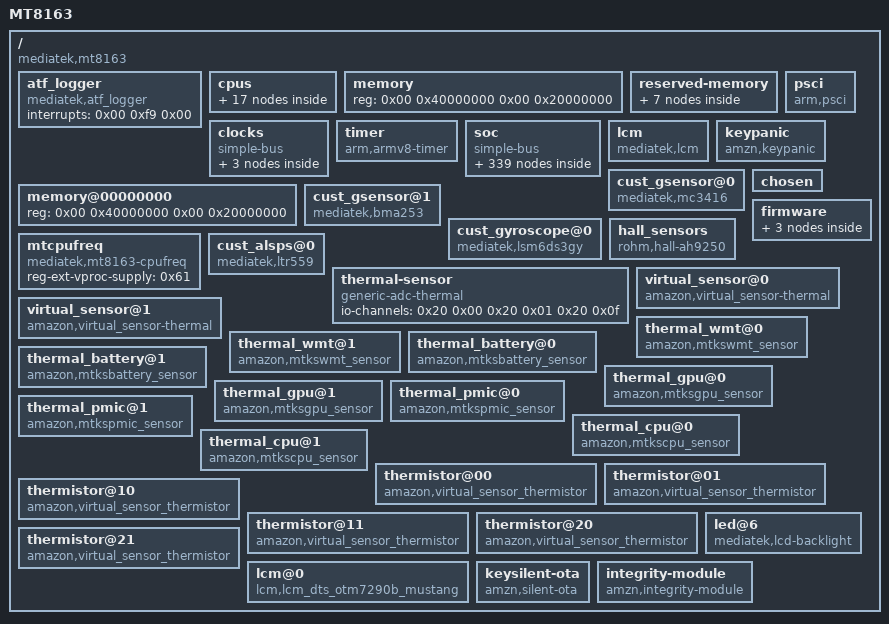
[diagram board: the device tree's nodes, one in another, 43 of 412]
/dts-v1/;

/ {
	model = "MT8163";
	compatible = "mediatek,mt8163";
	interrupt-parent = <0x01>;
	#address-cells = <0x02>;
	#size-cells = <0x02>;
	version = "hvt";

	atf_logger {
		compatible = "mediatek,atf_logger";
		interrupts = <0x00 0xf9 0x00>;
	};

	cpus {
		#address-cells = <0x01>;
		#size-cells = <0x00>;

		cpu@0 {
			device_type = "cpu";
			compatible = "arm,cortex-a53";
			next-level-cache = <0x02>;
			reg = <0x00>;
			enable-method = "mt-boot";
			cpu-idle-states = <0x03 0x03 0x04 0x04 0x04>;
			cpu-release-addr = <0x00 0x40000200>;
			clock-frequency = "M|m";
			#cooling-cells = <0x02>;
			sched-energy-costs = <0x05 0x06>;
			linux,phandle = <0x07>;
			phandle = <0x07>;
		};

		cpu@1 {
			device_type = "cpu";
			compatible = "arm,cortex-a53";
			next-level-cache = <0x02>;
			reg = <0x01>;
			enable-method = "mt-boot";
			cpu-idle-states = <0x03 0x03 0x04 0x04 0x04>;
			cpu-release-addr = <0x00 0x40000200>;
			clock-frequency = "M|m";
			sched-energy-costs = <0x05 0x06>;
			linux,phandle = <0x08>;
			phandle = <0x08>;
		};

		cpu@2 {
			device_type = "cpu";
			compatible = "arm,cortex-a53";
			next-level-cache = <0x02>;
			reg = <0x02>;
			enable-method = "mt-boot";
			cpu-idle-states = <0x03 0x03 0x04 0x04 0x04>;
			cpu-release-addr = <0x00 0x40000200>;
			clock-frequency = "M|m";
			sched-energy-costs = <0x05 0x06>;
			linux,phandle = <0x09>;
			phandle = <0x09>;
		};

		cpu@3 {
			device_type = "cpu";
			compatible = "arm,cortex-a53";
			next-level-cache = <0x02>;
			reg = <0x03>;
			enable-method = "mt-boot";
			cpu-idle-states = <0x03 0x03 0x04 0x04 0x04>;
			cpu-release-addr = <0x00 0x40000200>;
			clock-frequency = "M|m";
			sched-energy-costs = <0x05 0x06>;
			linux,phandle = <0x0a>;
			phandle = <0x0a>;
		};

		cpu-map {

			cluster0 {

				core0 {
					cpu = <0x07>;
				};

				core1 {
					cpu = <0x08>;
				};

				core2 {
					cpu = <0x09>;
				};

				core3 {
					cpu = <0x0a>;
				};
			};
		};

		l2-cache0 {
			compatible = "cache";
			linux,phandle = <0x02>;
			phandle = <0x02>;
		};

		idle-states {
			entry-method = "arm,psci";

			cpu-sleep-0-0 {
				compatible = "arm,idle-state";
				arm,psci-suspend-param = <0x10000>;
				entry-latency-us = <0x258>;
				exit-latency-us = <0x258>;
				min-residency-us = <0x4b0>;
				linux,phandle = <0x04>;
				phandle = <0x04>;
			};

			cluster-sleep-0 {
				compatible = "arm,idle-state";
				arm,psci-suspend-param = <0x2010000>;
				entry-latency-us = <0x320>;
				exit-latency-us = <0x3e8>;
				min-residency-us = <0x7d0>;
				linux,phandle = <0x03>;
				phandle = <0x03>;
			};
		};

		energy-costs {

			mt8163-core-cost0 {
				busy-cost-data = <0x400 0x00>;
				idle-cost-data = <0x00 0x00>;
				linux,phandle = <0x05>;
				phandle = <0x05>;
			};

			mt8163-cluster-cost0 {
				busy-cost-data = <0x400 0x00>;
				idle-cost-data = <0x00 0x00>;
				linux,phandle = <0x06>;
				phandle = <0x06>;
			};
		};
	};

	memory {
		device_type = "memory";
		reg = <0x00 0x40000000 0x00 0x20000000>;
	};

	reserved-memory {
		#address-cells = <0x02>;
		#size-cells = <0x02>;
		ranges;
		linux,phandle = <0x62>;
		phandle = <0x62>;

		atf-reserved-memory {
			compatible = "mediatek,mt8163-atf-reserved-memory";
			no-map;
			reg = <0x00 0x43000000 0x00 0x30000>;
			linux,phandle = <0x63>;
			phandle = <0x63>;
		};

		ram_console-reserved-memory {
			compatible = "mediatek,ram_console";
			reg = <0x00 0x44400000 0x00 0x10000>;
		};

		pstore-reserved-memory {
			compatible = "mediatek,pstore";
			reg = <0x00 0x44410000 0x00 0xe0000>;
		};

		minirdump-reserved-memory {
			compatible = "mediatek,minirdump";
			reg = <0x00 0x444f0000 0x00 0x10000>;
		};

		consys-reserve-memory {
			compatible = "mediatek,consys-reserve-memory";
			no-map;
			size = <0x00 0x200000>;
			alignment = <0x00 0x200000>;
		};

		mdump-reserved-memory {
			compatible = "amazon,mdump-reserve-memory";
			reg = <0x00 0x4bd00000 0x00 0x300000>;
			linux,phandle = <0x64>;
			phandle = <0x64>;
		};

		secure-carveout {
			compatible = "shared-secure-pool";
			reusable;
			size = <0x00 0x4c00000>;
			alignment = <0x00 0x400000>;
			linux,phandle = <0x65>;
			phandle = <0x65>;
		};
	};

	psci {
		compatible = "arm,psci";
		method = "smc";
		cpu_suspend = <0x84000001>;
		cpu_off = <0x84000002>;
		cpu_on = <0x84000003>;
		affinity_info = <0x84000004>;
	};

	clocks {
		#address-cells = <0x02>;
		#size-cells = <0x02>;
		compatible = "simple-bus";
		ranges;

		clk_null {
			compatible = "fixed-clock";
			#clock-cells = <0x00>;
			clock-frequency = <0x00>;
			linux,phandle = <0x2f>;
			phandle = <0x2f>;
		};

		clk26m {
			compatible = "fixed-clock";
			#clock-cells = <0x00>;
			clock-frequency = <0x18cba80>;
			linux,phandle = <0x21>;
			phandle = <0x21>;
		};

		clk32k {
			compatible = "fixed-clock";
			#clock-cells = <0x00>;
			clock-frequency = <0x8000>;
			linux,phandle = <0x66>;
			phandle = <0x66>;
		};
	};

	timer {
		compatible = "arm,armv8-timer";
		interrupt-parent = <0x0b>;
		interrupts = <0x01 0x0d 0xf08 0x01 0x0e 0xf08 0x01 0x0b 0xf08 0x01 0x0a 0xf08>;
		clock-frequency = <0xc65d40>;
		arm,no-tick-in-suspend;
	};

	soc {
		#address-cells = <0x02>;
		#size-cells = <0x02>;
		compatible = "simple-bus";
		ranges;

		chipid@08000000 {
			compatible = "mediatek,mt8163-chipid";
			reg = <0x00 0x8000000 0x00 0x10>;
			linux,phandle = <0x67>;
			phandle = <0x67>;
		};

		topckgen@10000000 {
			compatible = "mediatek,mt8163-topckgen";
			reg = <0x00 0x10000000 0x00 0x1000>;
			#clock-cells = <0x01>;
			linux,phandle = <0x0d>;
			phandle = <0x0d>;
		};

		infracfg@10001000 {
			compatible = "mediatek,mt8163-infracfg\0syscon";
			reg = <0x00 0x10001000 0x00 0x1000>;
			#clock-cells = <0x01>;
			#reset-cells = <0x01>;
			linux,phandle = <0x0c>;
			phandle = <0x0c>;
		};

		syscfg_pctl_a@10005000 {
			compatible = "mediatek,mt8163-pctl-a-syscfg\0syscon";
			reg = <0x00 0x10005000 0x00 0x1000>;
			linux,phandle = <0x0e>;
			phandle = <0x0e>;
		};

		toprgu@10007000 {
			compatible = "mediatek,mt8163-rgu\0mediatek,mt6589-wdt";
			reg = <0x00 0x10007000 0x00 0x1000>;
			interrupts = <0x00 0x80 0x02>;
			#reset-cells = <0x01>;
			linux,phandle = <0x4e>;
			phandle = <0x4e>;
		};

		apxgpt@10008000 {
			compatible = "mediatek,mt8163-timer\0mediatek,mt6577-timer";
			reg = <0x00 0x10008000 0x00 0x1000>;
			interrupts = <0x00 0x98 0x08>;
			clocks = <0x0c 0x06 0x0c 0x46 0x0d 0x60>;
			clock-names = "bus\0clk13m\0clk32k";
			linux,phandle = <0x68>;
			phandle = <0x68>;
		};

		pmu {
			compatible = "arm,armv8-pmuv3\0arm,cortex-a7-pmu";
			interrupts = <0x00 0x08 0x08 0x00 0x09 0x08 0x00 0x0a 0x08 0x00 0x0b 0x08>;
			interrupt-affinity = <0x07 0x08 0x09 0x0a>;
		};

		pinctrl@10005000 {
			compatible = "mediatek,mt8163-pinctrl";
			reg = <0x00 0x1000b000 0x00 0x1000>;
			mediatek,pctl-regmap = <0x0e>;
			pins-are-numbered;
			gpio-controller;
			#gpio-cells = <0x02>;
			interrupt-controller;
			#interrupt-cells = <0x02>;
			interrupts = <0x00 0x99 0x04 0x00 0x9a 0x04 0x00 0x9b 0x04>;
			pinctrl-names = "default";
			pinctrl-0 = <0x0f>;
			linux,phandle = <0x10>;
			phandle = <0x10>;

			spi1 {
				linux,phandle = <0x1e>;
				phandle = <0x1e>;

				pins_spi {
					pinmux = <0x3501 0x3601 0x3701 0x3801>;
					bias-disable;
					drive-strength = <0x02>;
					linux,phandle = <0x69>;
					phandle = <0x69>;
				};
			};

			uart0_pin_default {
				linux,phandle = <0x12>;
				phandle = <0x12>;

				pins_rx {
					pinmux = <0x4f01>;
					input-enable;
					bias-pull-up;
				};

				pins_tx {
					pinmux = <0x5001>;
				};
			};

			pinconf_default {
				linux,phandle = <0x0f>;
				phandle = <0x0f>;
			};

			eint4default {
				linux,phandle = <0x58>;
				phandle = <0x58>;
			};

			eint4 {
				linux,phandle = <0x59>;
				phandle = <0x59>;

				pins_cmd_dat {
					pinmux = <0x1a00>;
					bias-disable;
				};
			};

			bq24297_int_pin {
				linux,phandle = <0x19>;
				phandle = <0x19>;

				pins_cmd_dat {
					pinmux = <0x2b00>;
					input-enable;
					bias-pull-up;
				};
			};

			bq24297_chg_en_pin {
				linux,phandle = <0x18>;
				phandle = <0x18>;

				pins_cmd_dat {
					pinmux = <0x1800>;
					slew-rate = <0x01>;
					bias-disable;
					output-low;
				};
			};

			alspspincfg {
				linux,phandle = <0x5f>;
				phandle = <0x5f>;

				pins_cmd_dat {
					pinmux = <0x2000>;
					slew-rate = <0x00>;
					bias-pull-up = <0x00>;
				};
			};

			alspsdefaultcfg {
				linux,phandle = <0x5e>;
				phandle = <0x5e>;
			};

			audiodefault {
				linux,phandle = <0x28>;
				phandle = <0x28>;
			};

			rt551x_irq_init {
				linux,phandle = <0x15>;
				phandle = <0x15>;

				pins_cmd_dat {
					pinmux = <0x1c00>;
					bias-pull-down;
				};
			};

			pmicclkmode0 {
				linux,phandle = <0x29>;
				phandle = <0x29>;

				pins_cmd0_dat {
					pinmux = <0x700>;
				};

				pins_cmd1_dat {
					pinmux = <0x800>;
				};

				pins_cmd2_dat {
					pinmux = <0x900>;
				};
			};

			pmicclkmode1 {
				linux,phandle = <0x2a>;
				phandle = <0x2a>;

				pins_cmd0_dat {
					pinmux = <0x701>;
				};

				pins_cmd1_dat {
					pinmux = <0x801>;
				};

				pins_cmd2_dat {
					pinmux = <0x901>;
				};
			};

			camdefault {
				linux,phandle = <0x3b>;
				phandle = <0x3b>;
			};

			cam0@0 {
				linux,phandle = <0x3c>;
				phandle = <0x3c>;

				pins_cmd_dat {
					pinmux = <0x1200>;
					slew-rate = <0x01>;
					output-low;
				};
			};

			cam0@1 {
				linux,phandle = <0x3d>;
				phandle = <0x3d>;

				pins_cmd_dat {
					pinmux = <0x1200>;
					slew-rate = <0x01>;
					output-high;
				};
			};

			cam0@2 {
				linux,phandle = <0x3e>;
				phandle = <0x3e>;

				pins_cmd_dat {
					pinmux = <0x1400>;
					slew-rate = <0x01>;
					output-low;
				};
			};

			cam0@3 {
				linux,phandle = <0x3f>;
				phandle = <0x3f>;

				pins_cmd_dat {
					pinmux = <0x1400>;
					slew-rate = <0x01>;
					output-high;
				};
			};

			cam1@0 {
				linux,phandle = <0x40>;
				phandle = <0x40>;

				pins_cmd_dat {
					pinmux = <0x1300>;
					slew-rate = <0x01>;
					output-low;
				};
			};

			cam1@1 {
				linux,phandle = <0x41>;
				phandle = <0x41>;

				pins_cmd_dat {
					pinmux = <0x1300>;
					slew-rate = <0x01>;
					output-high;
				};
			};

			cam1@2 {
				linux,phandle = <0x42>;
				phandle = <0x42>;

				pins_cmd_dat {
					pinmux = <0x1500>;
					slew-rate = <0x01>;
					output-low;
				};
			};

			cam1@3 {
				linux,phandle = <0x43>;
				phandle = <0x43>;

				pins_cmd_dat {
					pinmux = <0x1500>;
					slew-rate = <0x01>;
					output-high;
				};
			};

			cam_pin_rdn0 {
				linux,phandle = <0x45>;
				phandle = <0x45>;

				pins_cmd_dat {
					pinmux = <0x6501>;
				};
			};

			cam_pin_rdp0 {
				linux,phandle = <0x46>;
				phandle = <0x46>;

				pins_cmd_dat {
					pinmux = <0x6601>;
				};
			};

			cam_pin_rcn {
				linux,phandle = <0x47>;
				phandle = <0x47>;

				pins_cmd_dat {
					pinmux = <0x6901>;
				};
			};

			cam_pin_rcp {
				linux,phandle = <0x48>;
				phandle = <0x48>;

				pins_cmd_dat {
					pinmux = <0x6a01>;
				};
			};

			cam_pin_rcn_a {
				linux,phandle = <0x49>;
				phandle = <0x49>;

				pins_cmd_dat {
					pinmux = <0x6f01>;
				};
			};

			cam_pin_rcp_a {
				linux,phandle = <0x4a>;
				phandle = <0x4a>;

				pins_cmd_dat {
					pinmux = <0x7001>;
				};
			};

			cam_pin_rdn0_a {
				linux,phandle = <0x4b>;
				phandle = <0x4b>;

				pins_cmd_dat {
					pinmux = <0x7301>;
				};
			};

			cam_pin_rdp0_a {
				linux,phandle = <0x4c>;
				phandle = <0x4c>;

				pins_cmd_dat {
					pinmux = <0x7401>;
				};
			};

			cam_pin_mclk {
				linux,phandle = <0x44>;
				phandle = <0x44>;

				pins_cmd_dat {
					pinmux = <0x7701>;
				};
			};

			default {
				linux,phandle = <0x4f>;
				phandle = <0x4f>;
			};

			eint0default {
				linux,phandle = <0x5a>;
				phandle = <0x5a>;

				pins_cmd_dat {
					pinmux = <0x1600>;
					slew-rate = <0x00>;
					bias-disable;
				};
			};

			eint@0 {
				linux,phandle = <0x1b>;
				phandle = <0x1b>;

				pins_cmd_dat {
					pinmux = <0x1600>;
					slew-rate = <0x00>;
					bias-disable;
				};
			};

			eintoutput0 {
				linux,phandle = <0x1a>;
				phandle = <0x1a>;

				pins_cmd_dat {
					pinmux = <0x1600>;
					slew-rate = <0x01>;
					output-low;
				};
			};

			eintoutput1 {
				linux,phandle = <0x5b>;
				phandle = <0x5b>;

				pins_cmd_dat {
					pinmux = <0x1600>;
					slew-rate = <0x01>;
					output-high;
				};
			};

			rstoutput0 {
				linux,phandle = <0x5c>;
				phandle = <0x5c>;

				pins_cmd_dat {
					pinmux = <0x2d00>;
					slew-rate = <0x01>;
					output-low;
				};
			};

			rstoutput1 {
				linux,phandle = <0x5d>;
				phandle = <0x5d>;

				pins_cmd_dat {
					pinmux = <0x2d00>;
					slew-rate = <0x01>;
					output-high;
				};
			};

			iddig_irq_init {
				linux,phandle = <0x23>;
				phandle = <0x23>;

				pins_cmd_dat {
					pinmux = <0x2600>;
					bias-pull-up;
				};
			};

			iddig_irq_low {
				linux,phandle = <0x24>;
				phandle = <0x24>;

				pins_cmd_dat {
					pinmux = <0x2600>;
					bias-pull-down;
				};
			};

			iddig_irq_high {
				linux,phandle = <0x25>;
				phandle = <0x25>;

				pins_cmd_dat {
					pinmux = <0x2600>;
					bias-pull-up;
				};
			};

			gpslna@0 {
				linux,phandle = <0x50>;
				phandle = <0x50>;

				pins_cmd_dat {
					pinmux = <0x600>;
					slew-rate = <0x00>;
					bias-disable;
					output-low;
				};
			};

			gpslna@1 {
				linux,phandle = <0x51>;
				phandle = <0x51>;

				pins_cmd_dat {
					pinmux = <0x600>;
					slew-rate = <0x01>;
					output-high;
				};
			};

			gpslna@2 {
				linux,phandle = <0x52>;
				phandle = <0x52>;

				pins_cmd_dat {
					pinmux = <0x600>;
					slew-rate = <0x01>;
					output-low;
				};
			};

			wifireset@0 {
				linux,phandle = <0x53>;
				phandle = <0x53>;

				pins_reset_dat {
					pinmux = <0x3c01 0x3f01 0x4001 0x4101>;
					input-enable;
					bias-pull-up;
				};
			};

			i2c0@0 {
				linux,phandle = <0x14>;
				phandle = <0x14>;

				pins1 {
					pinmux = <0x4b01 0x4c01>;
					bias-disable;
				};
			};

			i2c1@0 {
				linux,phandle = <0x16>;
				phandle = <0x16>;

				pins1 {
					pinmux = <0x3901 0x3a01>;
					bias-disable;
				};
			};

			i2c2@0 {
				linux,phandle = <0x17>;
				phandle = <0x17>;

				pins1 {
					pinmux = <0x4d01 0x4e01>;
					bias-disable;
				};
			};

			lcm_gpio@49_high {
				linux,phandle = <0x6a>;
				phandle = <0x6a>;

				pins_cmd_dat {
					pinmux = <0x3100>;
					slew-rate = <0x01>;
					output-high;
				};
			};

			lcm_gpio@49_low {
				linux,phandle = <0x6b>;
				phandle = <0x6b>;

				pins_cmd_dat {
					pinmux = <0x3100>;
					slew-rate = <0x01>;
					output-low;
				};
			};

			lcm_gpio@48_high {
				linux,phandle = <0x6c>;
				phandle = <0x6c>;

				pins_cmd_dat {
					pinmux = <0x3000>;
					slew-rate = <0x01>;
					output-high;
				};
			};

			lcm_gpio@48_low {
				linux,phandle = <0x6d>;
				phandle = <0x6d>;

				pins_cmd_dat {
					pinmux = <0x3000>;
					slew-rate = <0x01>;
					output-low;
				};
			};

			lcm_gpio@50_high {
				linux,phandle = <0x6e>;
				phandle = <0x6e>;

				pins_cmd_dat {
					pinmux = <0x3200>;
					bias-disable;
				};
			};

			lcm_gpio@50_low {
				linux,phandle = <0x6f>;
				phandle = <0x6f>;

				pins_cmd_dat {
					pinmux = <0x3200>;
					bias-disable;
				};
			};

			mmc0default {
				linux,phandle = <0x2b>;
				phandle = <0x2b>;

				pins_cmd_dat {
					pinmux = <0x8901 0x8801 0x8701 0x8601 0x8201 0x8101 0x8001 0x7f01 0x8401>;
					input-enable;
					bias-pull-up;
				};

				pins_clk {
					pinmux = <0x8501>;
					bias-pull-down;
				};

				pins_rst {
					pinmux = <0x8301>;
					bias-pull-up;
				};
			};

			mmc0@0 {
				linux,phandle = <0x2c>;
				phandle = <0x2c>;

				pins_cmd_dat {
					pinmux = <0x8901 0x8801 0x8701 0x8601 0x8201 0x8101 0x8001 0x7f01 0x8401>;
					input-enable;
					drive-strength = <0x06>;
					bias-pull-up = <0x65>;
				};

				pins_clk {
					pinmux = <0x8501>;
					drive-strength = <0x06>;
					bias-pull-down = <0x65>;
				};

				pins_rst {
					pinmux = <0x8301>;
					bias-pull-up;
				};
			};

			mmc1default {
				linux,phandle = <0x30>;
				phandle = <0x30>;

				pins_cmd_dat {
					pinmux = <0x7b01 0x7c01 0x7d01 0x7e01 0x7901>;
					input-enable;
					drive-strength = <0x06>;
					bias-pull-up = <0x65>;
				};

				pins_clk {
					pinmux = <0x7a01>;
					drive-strength = <0x06>;
					bias-pull-down = <0x66>;
				};

				pins_insert {
					pinmux = <0x3400>;
					bias-pull-up;
				};
			};

			mmc1@0 {
				linux,phandle = <0x31>;
				phandle = <0x31>;

				pins_cmd_dat {
					pinmux = <0x7b01 0x7c01 0x7d01 0x7e01 0x7901>;
					input-enable;
					drive-strength = <0x08>;
					bias-pull-up = <0x66>;
				};

				pins_clk {
					pinmux = <0x7a01>;
					drive-strength = <0x08>;
					bias-pull-down = <0x66>;
				};
			};
		};

		dramco@10004000 {
			compatible = "mediatek,mt8163-dramco";
			reg = <0x00 0x10004000 0x00 0x1000>;
			linux,phandle = <0x70>;
			phandle = <0x70>;
		};

		scpsys@10006000 {
			compatible = "mediatek,mt8163-scpsys\0syscon";
			#power-domain-cells = <0x01>;
			reg = <0x00 0x10006000 0x00 0x1000>;
			interrupts = <0x00 0xa3 0x08 0x00 0xa4 0x08 0x00 0xa5 0x08 0x00 0xa6 0x08 0x00 0xa7 0x08 0x00 0xa8 0x08 0x00 0xa9 0x08 0x00 0xaa 0x08>;
			infracfg = <0x0c>;
			clocks = <0x0d 0x46 0x0d 0x43>;
			clock-names = "mfg\0mm";
			linux,phandle = <0x27>;
			phandle = <0x27>;
		};

		hacc@1000a000 {
			compatible = "mediatek,hacc";
			reg = <0x00 0x1000a000 0x00 0x1000>;
			clocks = <0x0c 0x05>;
			clock-names = "main";
		};

		apmixedsys@1000c000 {
			compatible = "mediatek,mt8163-apmixedsys";
			reg = <0x00 0x1000c000 0x00 0x1000>;
			#clock-cells = <0x01>;
			linux,phandle = <0x1f>;
			phandle = <0x1f>;
		};

		fhctl@1000cf00 {
			compatible = "mediatek,mt8163-fhctl";
			reg = <0x00 0x1000cf00 0x00 0x100>;
		};

		pwrap@0x1000d000 {
			compatible = "mediatek,mt8163-pwrap";
			reg = <0x00 0x1000d000 0x00 0x1000>;
			reg-names = "pwrap";
			interrupts = <0x00 0xa1 0x04>;
			clocks = <0x0d 0x51 0x0c 0x01>;
			clock-names = "spi\0wrap";
			linux,phandle = <0x71>;
			phandle = <0x71>;

			mt6323 {
				compatible = "mediatek,mt6323";
				linux,phandle = <0x72>;
				phandle = <0x72>;

				pmicmt6323 {
					compatible = "mediatek,mt6323-pmic";
					interrupt-parent = <0x10>;
					interrupts = <0x18 0x04>;
					linux,phandle = <0x73>;
					phandle = <0x73>;
				};

				regulators {
					compatible = "mediatek,mt6323-regulator";

					buck_vproc {
						regulator-name = "vproc";
						regulator-min-microvolt = <0xaae60>;
						regulator-max-microvolt = <0x149970>;
						regulator-ramp-delay = <0x30d4>;
						regulator-always-on;
						regulator-boot-on;
						linux,phandle = <0x74>;
						phandle = <0x74>;
					};

					buck_vsys {
						regulator-name = "vsys";
						regulator-min-microvolt = <0x155cc0>;
						regulator-max-microvolt = <0x2d95ec>;
						regulator-ramp-delay = <0x61a8>;
						regulator-always-on;
						regulator-boot-on;
						linux,phandle = <0x75>;
						phandle = <0x75>;
					};

					buck_vpa {
						regulator-name = "vpa";
						regulator-min-microvolt = <0x7a120>;
						regulator-max-microvolt = <0x37b1d0>;
						linux,phandle = <0x76>;
						phandle = <0x76>;
					};

					ldo_vtcxo {
						regulator-name = "vtcxo";
						regulator-min-microvolt = <0x2ab980>;
						regulator-max-microvolt = <0x2ab980>;
						regulator-enable-ramp-delay = <0x5a>;
						regulator-always-on;
						regulator-boot-on;
						linux,phandle = <0x77>;
						phandle = <0x77>;
					};

					ldo_vcn28 {
						regulator-name = "vcn28";
						regulator-min-microvolt = <0x2ab980>;
						regulator-max-microvolt = <0x2ab980>;
						regulator-enable-ramp-delay = <0xb9>;
						linux,phandle = <0x55>;
						phandle = <0x55>;
					};

					ldo_vcn33_bt {
						regulator-name = "vcn33_bt";
						regulator-min-microvolt = <0x325aa0>;
						regulator-max-microvolt = <0x36ee80>;
						regulator-enable-ramp-delay = <0xb9>;
						linux,phandle = <0x56>;
						phandle = <0x56>;
					};

					ldo_vcn33_wifi {
						regulator-name = "vcn33_wifi";
						regulator-min-microvolt = <0x325aa0>;
						regulator-max-microvolt = <0x36ee80>;
						regulator-enable-ramp-delay = <0xb9>;
						linux,phandle = <0x57>;
						phandle = <0x57>;
					};

					ldo_va {
						regulator-name = "va";
						regulator-min-microvolt = <0x2ab980>;
						regulator-max-microvolt = <0x2ab980>;
						regulator-enable-ramp-delay = <0xd8>;
						regulator-always-on;
						regulator-boot-on;
						linux,phandle = <0x78>;
						phandle = <0x78>;
					};

					ldo_vcama {
						regulator-name = "vcama";
						regulator-min-microvolt = <0x16e360>;
						regulator-max-microvolt = <0x2ab980>;
						regulator-enable-ramp-delay = <0xd8>;
						linux,phandle = <0x38>;
						phandle = <0x38>;
					};

					ldo_vio28 {
						regulator-name = "vio28";
						regulator-min-microvolt = <0x2ab980>;
						regulator-max-microvolt = <0x2ab980>;
						regulator-enable-ramp-delay = <0xd8>;
						regulator-always-on;
						regulator-boot-on;
						linux,phandle = <0x79>;
						phandle = <0x79>;
					};

					ldo_vusb {
						regulator-name = "vusb";
						regulator-min-microvolt = <0x325aa0>;
						regulator-max-microvolt = <0x325aa0>;
						regulator-enable-ramp-delay = <0xd8>;
						regulator-boot-on;
						linux,phandle = <0x22>;
						phandle = <0x22>;
					};

					ldo_vmc {
						regulator-name = "vmc";
						regulator-min-microvolt = <0x1b7740>;
						regulator-max-microvolt = <0x325aa0>;
						regulator-enable-ramp-delay = <0x24>;
						regulator-boot-on;
						linux,phandle = <0x33>;
						phandle = <0x33>;
					};

					ldo_vmch {
						regulator-name = "vmch";
						regulator-min-microvolt = <0x2dc6c0>;
						regulator-max-microvolt = <0x325aa0>;
						regulator-enable-ramp-delay = <0x24>;
						regulator-boot-on;
						linux,phandle = <0x32>;
						phandle = <0x32>;
					};

					ldo_vemc3v3 {
						regulator-name = "vemc3v3";
						regulator-min-microvolt = <0x2dc6c0>;
						regulator-max-microvolt = <0x325aa0>;
						regulator-enable-ramp-delay = <0x24>;
						regulator-boot-on;
						linux,phandle = <0x2d>;
						phandle = <0x2d>;
					};

					ldo_vgp1 {
						regulator-name = "vgp1";
						regulator-min-microvolt = <0x124f80>;
						regulator-max-microvolt = <0x325aa0>;
						regulator-enable-ramp-delay = <0xd8>;
						linux,phandle = <0x60>;
						phandle = <0x60>;
					};

					ldo_vgp2 {
						regulator-name = "vgp2";
						regulator-min-microvolt = <0x124f80>;
						regulator-max-microvolt = <0x2dc6c0>;
						regulator-enable-ramp-delay = <0xd8>;
						linux,phandle = <0x1c>;
						phandle = <0x1c>;
					};

					ldo_vgp3 {
						regulator-name = "vgp3";
						regulator-min-microvolt = <0x124f80>;
						regulator-max-microvolt = <0x1b7740>;
						regulator-enable-ramp-delay = <0xd8>;
						linux,phandle = <0x4d>;
						phandle = <0x4d>;
					};

					ldo_vcn18 {
						regulator-name = "vcn18";
						regulator-min-microvolt = <0x1b7740>;
						regulator-max-microvolt = <0x1b7740>;
						regulator-enable-ramp-delay = <0xd8>;
						linux,phandle = <0x54>;
						phandle = <0x54>;
					};

					ldo_vsim1 {
						regulator-name = "vsim1";
						regulator-min-microvolt = <0x1b7740>;
						regulator-max-microvolt = <0x2dc6c0>;
						regulator-enable-ramp-delay = <0xd8>;
						linux,phandle = <0x7a>;
						phandle = <0x7a>;
					};

					ldo_vsim2 {
						regulator-name = "vsim2";
						regulator-min-microvolt = <0x1b7740>;
						regulator-max-microvolt = <0x2dc6c0>;
						regulator-enable-ramp-delay = <0xd8>;
						linux,phandle = <0x7b>;
						phandle = <0x7b>;
					};

					ldo_vrtc {
						regulator-name = "vrtc";
						regulator-min-microvolt = <0x2ab980>;
						regulator-max-microvolt = <0x2ab980>;
						regulator-always-on;
						regulator-boot-on;
						linux,phandle = <0x7c>;
						phandle = <0x7c>;
					};

					ldo_vcamaf {
						regulator-name = "vcamaf";
						regulator-min-microvolt = <0x124f80>;
						regulator-max-microvolt = <0x325aa0>;
						regulator-enable-ramp-delay = <0xd8>;
						linux,phandle = <0x1d>;
						phandle = <0x1d>;
					};

					ldo_vibr {
						regulator-name = "vibr";
						regulator-min-microvolt = <0x124f80>;
						regulator-max-microvolt = <0x325aa0>;
						regulator-enable-ramp-delay = <0x24>;
						linux,phandle = <0x7d>;
						phandle = <0x7d>;
					};

					ldo_vrf18 {
						regulator-name = "vrf18";
						regulator-min-microvolt = <0x1bd8e8>;
						regulator-max-microvolt = <0x1bd8e8>;
						regulator-enable-ramp-delay = <0xbb>;
						regulator-boot-on;
						linux,phandle = <0x7e>;
						phandle = <0x7e>;
					};

					ldo_vm {
						regulator-name = "vm";
						regulator-min-microvolt = <0x124f80>;
						regulator-max-microvolt = <0x1b7740>;
						regulator-enable-ramp-delay = <0xd8>;
						regulator-always-on;
						regulator-boot-on;
						linux,phandle = <0x7f>;
						phandle = <0x7f>;
					};

					ldo_vio18 {
						regulator-name = "vio18";
						regulator-min-microvolt = <0x1b7740>;
						regulator-max-microvolt = <0x1b7740>;
						regulator-enable-ramp-delay = <0xd8>;
						regulator-always-on;
						regulator-boot-on;
						linux,phandle = <0x2e>;
						phandle = <0x2e>;
					};

					ldo_vcamd {
						regulator-name = "vcamd";
						regulator-min-microvolt = <0x124f80>;
						regulator-max-microvolt = <0x1b7740>;
						regulator-enable-ramp-delay = <0xd8>;
						linux,phandle = <0x39>;
						phandle = <0x39>;
					};

					ldo_vcamio {
						regulator-name = "vcamio";
						regulator-min-microvolt = <0x1b7740>;
						regulator-max-microvolt = <0x1b7740>;
						regulator-enable-ramp-delay = <0xd8>;
						linux,phandle = <0x3a>;
						phandle = <0x3a>;
					};
				};
			};
		};

		devapc_ao@1000e000 {
			compatible = "mediatek,mt8163-devapc_ao";
			reg = <0x00 0x1000e000 0x00 0x1000>;
		};

		ddrphy@1000f000 {
			compatible = "mediatek,mt8163-ddrphy\0mediatek,ddrphy";
			reg = <0x00 0x1000f000 0x00 0x1000>;
			clocks = <0x0c 0x36>;
			clock-names = "dramc_f26m";
			linux,phandle = <0x80>;
			phandle = <0x80>;
		};

		keypad@10010000 {
			compatible = "mediatek,mt8163-keypad\0mediatek,kp";
			reg = <0x00 0x10010000 0x00 0x1000>;
			interrupts = <0x00 0xa2 0x02>;
			mediatek,kpd-key-debounce = <0x400>;
			mediatek,kpd-sw-pwrkey = <0x74>;
			mediatek,kpd-hw-pwrkey = <0x08>;
			mediatek,kpd-sw-rstkey = <0x73>;
			mediatek,kpd-hw-rstkey = <0x11>;
			mediatek,kpd-use-extend-type = <0x00>;
			mediatek,kpd-hw-map-num = <0x48>;
			mediatek,kpd-hw-init-map = <0x72 0x00 0x00 0x00 0x00 0x00 0x00 0x00 0x00 0x00 0x00 0x00 0x00 0x00 0x00 0x00 0x00 0x00 0x00 0x00 0x00 0x00 0x00 0x00 0x00 0x00 0x00 0x00 0x00 0x00 0x00 0x00 0x00 0x00 0x00 0x00 0x00 0x00 0x00 0x00 0x00 0x00 0x00 0x00 0x00 0x00 0x00 0x00 0x00 0x00 0x00 0x00 0x00 0x00 0x00 0x00 0x00 0x00 0x00 0x00 0x00 0x00 0x00 0x00 0x00 0x00 0x00 0x00 0x00 0x00 0x00 0x00>;
			mediatek,kpd-pwrkey-eint-gpio = <0x00>;
			mediatek,kpd-pwkey-gpio-din = <0x00>;
			mediatek,kpd-hw-dl-key0 = <0x00>;
			mediatek,kpd-hw-dl-key1 = <0x11>;
			mediatek,kpd-hw-dl-key2 = <0x08>;
			mediatek,kpd-hw-recovery-key = <0x00>;
			mediatek,kpd-hw-factory-key = <0x11>;
			linux,phandle = <0x81>;
			phandle = <0x81>;
		};

		md32@10020000 {
			compatible = "mediatek,mt8163-md32";
			reg = <0x00 0x10020000 0x00 0x38000 0x00 0x10058000 0x00 0x400 0x00 0x10059000 0x00 0x400>;
			interrupts = <0x00 0xae 0x04>;
			clocks = <0x0c 0x04>;
			clock-names = "sys";
			status = "okay";
			linux,phandle = <0x82>;
			phandle = <0x82>;
		};

		mcucfg@10200000 {
			compatible = "mediatek,mt8173-mcucfg\0syscon";
			reg = <0x00 0x10200000 0x00 0x1000>;
			linux,phandle = <0x83>;
			phandle = <0x83>;
		};

		cpuxgpt@10200000 {
			compatible = "mediatek,mt8163-cpuxgpt";
			interrupts = <0x00 0x40 0x04 0x00 0x41 0x04 0x00 0x42 0x04 0x00 0x43 0x04>;
			linux,phandle = <0x84>;
			phandle = <0x84>;
		};

		lastpc@10200000 {
			compatible = "mediatek,mt8163-mcucfg";
			reg = <0x00 0x10200000 0x00 0x200>;
			linux,phandle = <0x85>;
			phandle = <0x85>;
		};

		intpol-controller@10200620 {
			compatible = "mediatek,mt8163-sysirq\0mediatek,mt6577-sysirq";
			interrupt-controller;
			#interrupt-cells = <0x03>;
			interrupt-parent = <0x0b>;
			reg = <0x00 0x10200620 0x00 0x20>;
			linux,phandle = <0x01>;
			phandle = <0x01>;
		};

		emi@10203000 {
			compatible = "mediatek,mt8163-emi\0mediatek,emi";
			reg = <0x00 0x10203000 0x00 0x1000>;
			interrupts = <0x00 0x85 0x08>;
			linux,phandle = <0x86>;
			phandle = <0x86>;
		};

		sys_cirq@10204000 {
			compatible = "mediatek,mt8163-sys_cirq\0mediatek,mt6735-sys_cirq";
			reg = <0x00 0x10204000 0x00 0x1000>;
			interrupts = <0x00 0xf0 0x08>;
			mediatek,cirq_num = <0xa9>;
			mediatek,spi_start_offset = <0x48>;
			linux,phandle = <0x87>;
			phandle = <0x87>;
		};

		m4u@10205000 {
			cell-index = <0x00>;
			compatible = "mediatek,mt8163-m4u";
			reg = <0x00 0x10205000 0x00 0x1000>;
			interrupts = <0x00 0x93 0x08>;
		};

		devapc@10207000 {
			compatible = "mediatek,mt8163-devapc";
			reg = <0x00 0x10207000 0x00 0x1000>;
			interrupts = <0x00 0x85 0x08>;
			clocks = <0x0c 0x2b>;
			clock-names = "main";
		};

		systracker@10208000 {
			compatible = "mediatek,bus_dbg-v1";
			reg = <0x00 0x10208000 0x00 0x1000>;
			interrupts = <0x00 0x84 0x08>;
			linux,phandle = <0x88>;
			phandle = <0x88>;
		};

		dramc_nao@1020e000 {
			compatible = "mediatek,mt8163-dramc_nao\0mediatek,dramc_nao";
			reg = <0x00 0x1020e000 0x00 0x1000>;
			linux,phandle = <0x89>;
			phandle = <0x89>;
		};

		gcpu@10210000 {
			compatible = "mediatek,mt8163-gcpu";
			reg = <0x00 0x10210000 0x00 0x1000>;
			clocks = <0x0c 0x20>;
			clock-names = "main";
			linux,phandle = <0x8a>;
			phandle = <0x8a>;
		};

		gce@10212000 {
			compatible = "mediatek,mt8163-gce";
			reg = <0x00 0x10212000 0x00 0x1000>;
			interrupts = <0x00 0x8f 0x08 0x00 0x90 0x08>;
			disp_mutex_reg = <0x14015000 0x1000>;
			g3d_config_base = <0x13000000 0x00 0xffff0000>;
			mmsys_config_base = <0x14000000 0x01 0xffff0000>;
			disp_dither_base = <0x14010000 0x02 0xffff0000>;
			mm_na_base = <0x14020000 0x03 0xffff0000>;
			imgsys_base = <0x15000000 0x04 0xffff0000>;
			vdec_gcon_base = <0x16000000 0x05 0xffff0000>;
			venc_gcon_base = <0x17000000 0x06 0xffff0000>;
			conn_peri_base = <0x18000000 0x07 0xffff0000>;
			topckgen_base = <0x10000000 0x08 0xffff0000>;
			kp_base = <0x10010000 0x09 0xffff0000>;
			scp_sram_base = <0x10020000 0x0a 0xffff0000>;
			infra_na3_base = <0x10030000 0x0b 0xffff0000>;
			infra_na4_base = <0x10040000 0x0c 0xffff0000>;
			scp_base = <0x10050000 0x0d 0xffff0000>;
			mcucfg_base = <0x10200000 0x0e 0xffff0000>;
			gcpu_base = <0x10210000 0x0f 0xffff0000>;
			usb0_base = <0x11200000 0x10 0xffff0000>;
			usb_sif_base = <0x11210000 0x11 0xffff0000>;
			audio_base = <0x11220000 0x12 0xffff0000>;
			msdc0_base = <0x11230000 0x13 0xffff0000>;
			msdc1_base = <0x11240000 0x14 0xffff0000>;
			msdc2_base = <0x11250000 0x15 0xffff0000>;
			msdc3_base = <0x11260000 0x16 0xffff0000>;
			mdp_rdma0_sof = <0x00>;
			mdp_rsz0_sof = <0x01>;
			mdp_rsz1_sof = <0x02>;
			mdp_tdshp_sof = <0x03>;
			mdp_wdma_sof = <0x04>;
			mdp_wrot_sof = <0x05>;
			disp_ovl0_sof = <0x06>;
			disp_ovl1_sof = <0x07>;
			disp_rdma0_sof = <0x08>;
			disp_rdma1_sof = <0x09>;
			disp_wdma0_sof = <0x0a>;
			disp_color_sof = <0x0b>;
			disp_ccorr_sof = <0x0c>;
			disp_aal_sof = <0x0d>;
			disp_gamma_sof = <0x0e>;
			disp_dither_sof = <0x0f>;
			disp_ufoe_sof = <0x10>;
			disp_pwm0_sof = <0x11>;
			disp_wdma1_sof = <0x12>;
			ufod_rdma0_l0_sof = <0x13>;
			ufod_rdma0_l1_sof = <0x14>;
			ufod_rdma0_l2_sof = <0x15>;
			ufod_rdma0_l3_sof = <0x16>;
			ufod_rdma1_l0_sof = <0x17>;
			ufod_rdma1_l1_sof = <0x18>;
			ufod_rdma1_l2_sof = <0x19>;
			ufod_rdma1_l3_sof = <0x1a>;
			disp_dsc_sof = <0x1b>;
			mdp_rdma0_frame_done = <0x1c>;
			mdp_rsz0_frame_done = <0x1d>;
			mdp_rsz1_frame_done = <0x1e>;
			mdp_tdshp_frame_done = <0x1f>;
			mdp_wdma_frame_done = <0x20>;
			mdp_wrot_write_frame_done = <0x21>;
			mdp_wrot_read_frame_done = <0x22>;
			disp_ovl0_frame_done = <0x23>;
			disp_ovl1_frame_done = <0x24>;
			disp_rdma0_frame_done = <0x25>;
			disp_rdma1_frame_done = <0x26>;
			disp_wdma0_frame_done = <0x27>;
			disp_color_frame_done = <0x28>;
			disp_ccorr_frame_done = <0x29>;
			disp_aal_frame_done = <0x2a>;
			disp_gamma_frame_done = <0x2b>;
			disp_dither_frame_done = <0x2c>;
			disp_ufoe_frame_done = <0x2d>;
			disp_dpi0_frame_done = <0x2e>;
			disp_wdma1_frame_done = <0x2f>;
			ufod_rdma0_l0_frame_done = <0x30>;
			ufod_rdma0_l1_frame_done = <0x31>;
			ufod_rdma0_l2_frame_done = <0x32>;
			ufod_rdma0_l3_frame_done = <0x33>;
			ufod_rdma1_l0_frame_done = <0x34>;
			ufod_rdma1_l1_frame_done = <0x35>;
			ufod_rdma1_l2_frame_done = <0x36>;
			ufod_rdma1_l3_frame_done = <0x37>;
			disp_dpi1_frame_done = <0x38>;
			disp_dsc_frame_done = <0x39>;
			stream_done_0 = <0x3a>;
			stream_done_1 = <0x3b>;
			stream_done_2 = <0x3c>;
			stream_done_3 = <0x3d>;
			stream_done_4 = <0x3e>;
			stream_done_5 = <0x3f>;
			stream_done_6 = <0x40>;
			stream_done_7 = <0x41>;
			stream_done_8 = <0x42>;
			stream_done_9 = <0x43>;
			buf_underrun_event_0 = <0x44>;
			buf_underrun_event_1 = <0x45>;
			dsi0_te_event = <0x46>;
			isp_frame_done_b = <0x82>;
			isp_frame_done_a = <0x83>;
			isp_frame_done_p2_0 = <0x83>;
			isp_frame_done_p2_1 = <0x82>;
			seninf_1_fifo_full = <0x87>;
			venc_done = <0x101>;
			jpgenc_done = <0x102>;
			jpgdec_done = <0x103>;
			venc_mb_done = <0x104>;
			venc_128byte_cnt_done = <0x105>;
			clocks = <0x0c 0x09 0x11 0x00 0x11 0x01 0x11 0x02 0x11 0x03 0x11 0x04 0x11 0x05 0x11 0x06 0x11 0x08 0x11 0x07>;
			clock-names = "MT_CG_INFRA_GCE\0MT_CG_DISP0_SMI_COMMON\0MT_CG_DISP0_SMI_LARB0\0MT_CG_DISP0_CAM_MDP\0MT_CG_DISP0_MDP_RDMA\0MT_CG_DISP0_MDP_RSZ0\0MT_CG_DISP0_MDP_RSZ1\0MT_CG_DISP0_MDP_TDSHP\0MT_CG_DISP0_MDP_WROT\0MT_CG_DISP0_MDP_WDMA";
			linux,phandle = <0x8b>;
			phandle = <0x8b>;
		};

		perisys_iommu@10214000 {
			cell-index = <0x01>;
			compatible = "mediatek,mt8163-perisys_iommu";
			reg = <0x00 0x10214000 0x00 0x1000>;
			interrupts = <0x00 0x91 0x08>;
		};

		interrupt-controller@10221000 {
			compatible = "arm,gic-400";
			interrupt-controller;
			#interrupt-cells = <0x03>;
			interrupt-parent = <0x0b>;
			reg = <0x00 0x10221000 0x00 0x1000 0x00 0x10222000 0x00 0x1000 0x00 0x10224000 0x00 0x2000 0x00 0x10226000 0x00 0x2000>;
			interrupts = <0x01 0x09 0xf04>;
			linux,phandle = <0x0b>;
			phandle = <0x0b>;
		};

		btif_tx@11000700 {
			compatible = "mediatek,btif_tx";
			reg = <0x00 0x11000700 0x00 0x80>;
			interrupts = <0x00 0x6e 0x08>;
			linux,phandle = <0x8c>;
			phandle = <0x8c>;
		};

		btif_rx@11000780 {
			compatible = "mediatek,btif_rx";
			reg = <0x00 0x11000780 0x00 0x80>;
			interrupts = <0x00 0x6f 0x08>;
			linux,phandle = <0x8d>;
			phandle = <0x8d>;
		};

		dma-controller@0x11000300 {
			compatible = "mediatek,mt8163-uart-dma\0mediatek,mt6577-uart-dma";
			reg = <0x00 0x11000300 0x00 0x80 0x00 0x11000380 0x00 0x80 0x00 0x11000400 0x00 0x80 0x00 0x11000480 0x00 0x80 0x00 0x11000500 0x00 0x80 0x00 0x11000580 0x00 0x80 0x00 0x11000600 0x00 0x80 0x00 0x11000680 0x00 0x80>;
			interrupts = <0x00 0x66 0x08 0x00 0x67 0x08 0x00 0x68 0x08 0x00 0x69 0x08 0x00 0x6a 0x08 0x00 0x6b 0x08 0x00 0x6c 0x08 0x00 0x6d 0x08>;
			clocks = <0x0c 0x29>;
			clock-names = "apdma";
			#dma-cells = <0x01>;
			linux,phandle = <0x13>;
			phandle = <0x13>;
		};

		auxadc@11001000 {
			compatible = "mediatek,mt8163-auxadc\0mediatek,mt6735-auxadc";
			reg = <0x00 0x11001000 0x00 0x1000>;
			interrupts = <0x00 0x4c 0x02>;
			clocks = <0x0c 0x21>;
			clock-names = "main";
			#io-channel-cells = <0x01>;
			status = "okay";
			linux,phandle = <0x20>;
			phandle = <0x20>;
		};

		serial@11002000 {
			compatible = "mediatek,mt8163-uart\0mediatek,mt6577-uart";
			reg = <0x00 0x11002000 0x00 0x1000>;
			interrupts = <0x00 0x5b 0x08>;
			clocks = <0x0d 0x48 0x0c 0x13>;
			clock-names = "baud\0bus";
			pinctrl-names = "default";
			pinctrl-0 = <0x12>;
			status = "okay";
			linux,phandle = <0x8e>;
			phandle = <0x8e>;
		};

		serial@11003000 {
			compatible = "mediatek,mt8163-uart\0mediatek,mt6577-uart";
			reg = <0x00 0x11003000 0x00 0x1000>;
			interrupts = <0x00 0x5c 0x08>;
			clocks = <0x0d 0x48 0x0c 0x14>;
			clock-names = "baud\0bus";
			dmas = <0x13 0x02 0x13 0x03>;
			dma-names = "tx\0rx";
			status = "disabled";
			linux,phandle = <0x8f>;
			phandle = <0x8f>;
		};

		serial@11004000 {
			compatible = "mediatek,mt8163-uart\0mediatek,mt6577-uart";
			reg = <0x00 0x11004000 0x00 0x1000>;
			interrupts = <0x00 0x5d 0x08>;
			clocks = <0x0d 0x48 0x0c 0x15>;
			clock-names = "baud\0bus";
			dmas = <0x13 0x04 0x13 0x05>;
			dma-names = "tx\0rx";
			status = "disabled";
			linux,phandle = <0x90>;
			phandle = <0x90>;
		};

		serial@11005000 {
			compatible = "mediatek,mt8163-uart\0mediatek,mt6577-uart";
			reg = <0x00 0x11005000 0x00 0x1000>;
			interrupts = <0x00 0x5e 0x08>;
			clocks = <0x0d 0x48 0x0c 0x16>;
			clock-names = "baud\0bus";
			dmas = <0x13 0x06 0x13 0x07>;
			dma-names = "tx\0rx";
			status = "disabled";
			linux,phandle = <0x91>;
			phandle = <0x91>;
		};

		pwm@11006000 {
			compatible = "mediatek,pwm";
			reg = <0x00 0x11006000 0x00 0x1000>;
			interrupts = <0x00 0x4d 0x08>;
			clocks = <0x0c 0x0f 0x0c 0x10 0x0c 0x11 0x0c 0x12>;
			clock-names = "pwm1\0pwm2\0pwm3\0main";
			linux,phandle = <0x92>;
			phandle = <0x92>;
		};

		i2c@11007000 {
			compatible = "mediatek,mt8173-i2c";
			reg = <0x00 0x11007000 0x00 0x70 0x00 0x11000180 0x00 0x80>;
			interrupts = <0x00 0x54 0x08>;
			clock-div = <0x0a>;
			clocks = <0x0c 0x0b 0x0c 0x29>;
			clock-names = "main\0dma";
			#address-cells = <0x01>;
			#size-cells = <0x00>;
			status = "okay";
			clock-frequency = <0x61a80>;
			pinctrl-names = "default";
			pinctrl-0 = <0x14>;
			linux,phandle = <0x93>;
			phandle = <0x93>;

			lp8557_led@2c {
				compatible = "ti,lp855x-led";
				reg = <0x2c>;
				epprom_data = <0x14071301 0x1105122b 0x154216a0>;
			};

			kd_camera_hw1@3c {
				compatible = "mediatek,camera_main";
				reg = <0x3c>;
			};

			kd_camera_hw2@21 {
				compatible = "mediatek,camera_sub";
				reg = <0x21>;
			};

			audio-codec@57 {
				compatible = "realtek,rt551x";
				#sound-dai-cells = <0x00>;
				reg = <0x57>;
				interrupt-parent = <0x10>;
				interrupts = <0x06 0x04>;
				rt5518-irq = <0x10 0x1c 0x00>;
				rt5518-reset = <0x10 0x33 0x00>;
				pinctrl-names = "state_eint_as_int";
				pinctrl-0 = <0x15>;
				hw_analog_gain = <0x0e>;
				hw_digital_gain = <0x883b>;
				linux,phandle = <0x26>;
				phandle = <0x26>;
			};
		};

		i2c@11008000 {
			compatible = "mediatek,mt8173-i2c";
			reg = <0x00 0x11008000 0x00 0x70 0x00 0x11000200 0x00 0x80>;
			interrupts = <0x00 0x55 0x08>;
			clock-div = <0x0a>;
			clocks = <0x0c 0x0c 0x0c 0x29>;
			clock-names = "main\0dma";
			#address-cells = <0x01>;
			#size-cells = <0x00>;
			status = "okay";
			clock-frequency = <0x61a80>;
			pinctrl-names = "default";
			pinctrl-0 = <0x16>;
			linux,phandle = <0x94>;
			phandle = <0x94>;

			sym827@60 {
				compatible = "silergy,sym827-regulator";
				reg = <0x60>;
				regulator-name = "vproc";
				regulator-min-microvolt = <0x927c0>;
				regulator-max-microvolt = <0x152bec>;
				regulator-enable-ramp-delay = <0x190>;
				regulator-ramp-delay = <0x208d>;
				regulator-always-on;
				vsel-gpio = <0x10 0x22 0x00>;
				linux,phandle = <0x61>;
				phandle = <0x61>;
			};
		};

		i2c@11009000 {
			compatible = "mediatek,mt8173-i2c";
			reg = <0x00 0x11009000 0x00 0x70 0x00 0x11000280 0x00 0x80>;
			interrupts = <0x00 0x56 0x08>;
			clock-div = <0x0a>;
			clocks = <0x0c 0x0d 0x0c 0x29>;
			clock-names = "main\0dma";
			#address-cells = <0x01>;
			#size-cells = <0x00>;
			status = "okay";
			clock-frequency = <0x61a80>;
			pinctrl-names = "default";
			pinctrl-0 = <0x17>;
			linux,phandle = <0x95>;
			phandle = <0x95>;

			bq24296@6b {
				compatible = "ti,bq24297";
				reg = <0x6b>;
				interrupt-parent = <0x10>;
				interrupts = <0x0b 0x02>;
				pinctrl-names = "bq24297_chg_en\0bq24297_interrupt_init";
				pinctrl-0 = <0x18>;
				pinctrl-1 = <0x19>;
			};

			alsps@23 {
				compatible = "mediatek,alsps";
				reg = <0x23>;
			};

			tmp103-sensor@70 {
				compatible = "ti,tmp103_temp_sensor";
				reg = <0x70>;
				tmp103-sensor,offset = <0x8fc>;
				tmp103-sensor,alpha = <0x0a>;
				tmp103-sensor,weight = <0x00>;
			};

			tmp103-sensor@71 {
				compatible = "ti,tmp103_temp_sensor";
				reg = <0x71>;
				tmp103-sensor,offset = <0x2ee>;
				tmp103-sensor,alpha = <0x0a>;
				tmp103-sensor,weight = <0x00>;
			};

			tmp103-sensor@72 {
				compatible = "ti,tmp103_temp_sensor";
				reg = <0x72>;
				tmp103-sensor,offset = <0x2ee>;
				tmp103-sensor,alpha = <0x0a>;
				tmp103-sensor,weight = <0x00>;
			};

			g_sensor@4c {
				compatible = "mediatek,mc3416";
				reg = <0x4c>;
				status = "okay";
				i2c_num = <0x02>;
				i2c_addr = <0x4c 0x00 0x00 0x00>;
				direction = <0x06>;
				power_id = <0xffff>;
				power_vol = <0x00>;
				firlen = <0x00>;
				is_batch_supported = <0x00>;
			};

			g_sensor@18 {
				compatible = "mediatek,bma_gsensor";
				reg = <0x18>;
				status = "okay";
				i2c_num = <0x02>;
				i2c_addr = <0x18 0x00 0x00 0x00>;
				direction = <0x06>;
				power_id = <0xffff>;
				power_vol = <0x00>;
				firlen = <0x00>;
				is_batch_supported = <0x00>;
			};

			gyro_sensor@6c {
				compatible = "mediatek,gyro_sensor";
				reg = <0x6c>;
			};

			goodix_ts@5d {
				compatible = "goodix,gt9xx";
				reg = <0x5d>;
				pinctrl-names = "irq_as_gpio\0irq_as_int";
				pinctrl-0 = <0x1a>;
				pinctrl-1 = <0x1b>;
				vdd_ana-supply = <0x1c>;
				vcc_i2c-supply = <0x1d>;
				goodix,rst-gpio = <0x10 0x2d 0x00>;
				goodix,irq-gpio = <0x10 0x16 0x00>;
				goodix,cfg-group0 = <0x5b580200 0x4053d40 0x2082808 0x463c0305 0x00 0x13330f15 0x15191487 0x27dd6062 0x2a090000 0x9a021d 0x3c6c0000 0x32 0x55 0x6e82e201 0x140a0304 0x88570084 0x5b008060 0x7b6500 0x776b0077 0x00 0x00 0x00 0x200000 0x00 0x00 0x00 0xa0000 0x4000110f 0xf101112 0x13161718 0x191a1b1c 0x1d000102 0x3040506 0x708090c 0xd0e0000 0x242a 0x25292627 0x280a0b0c 0x90d080e 0x00 0x00 0x00 0x00 0x3c0000 0x00 0x00 0x3c303030 0x30303030 0x30303030 0x303c0000 0x00 0x00 0x00 0x00 0x00 0x00 0xcd01>;
				goodix,cfg-group1 = <0x5b580200 0x4053d40 0x2082808 0x463c0305 0x00 0x13330f15 0x15191487 0x27dd6062 0x2a090000 0x9a021d 0x3c6c0000 0x32 0x55 0x6e82e201 0x140a0304 0x88570084 0x5b008060 0x7b6500 0x776b0077 0x00 0x00 0x00 0x200000 0x00 0x00 0x00 0xa0000 0x4000110f 0xf101112 0x13161718 0x191a1b1c 0x1d000102 0x3040506 0x708090c 0xd0e0000 0x242a 0x25292627 0x280a0b0c 0x90d080e 0x00 0x00 0x00 0x00 0x3c0000 0x00 0x00 0x3c303030 0x30303030 0x30303030 0x303c0000 0x00 0x00 0x00 0x00 0x00 0x00 0xcd01>;
				goodix,cfg-group2 = <0x5b580200 0x4053d40 0x2082808 0x463c0305 0x00 0x13330f15 0x15191487 0x27dd6062 0x2a090000 0x9a021d 0x3c6c0000 0x32 0x55 0x6e82e201 0x140a0304 0x88570084 0x5b008060 0x7b6500 0x776b0077 0x00 0x00 0x00 0x200000 0x00 0x00 0x00 0xa0000 0x4000110f 0xf101112 0x13161718 0x191a1b1c 0x1d000102 0x3040506 0x708090c 0xd0e0000 0x242a 0x25292627 0x280a0b0c 0x90d080e 0x00 0x00 0x00 0x00 0x3c0000 0x00 0x00 0x3c303030 0x30303030 0x30303030 0x303c0000 0x00 0x00 0x00 0x00 0x00 0x00 0xcd01>;
				goodix,cfg-group3 = <0x5b580200 0x4053d40 0x2082808 0x463c0305 0x00 0x13330f15 0x15191487 0x27dd6062 0x2a090000 0x9a021d 0x3c6c0000 0x32 0x55 0x6e82e201 0x140a0304 0x88570084 0x5b008060 0x7b6500 0x776b0077 0x00 0x00 0x00 0x200000 0x00 0x00 0x00 0xa0000 0x4000110f 0xf101112 0x13161718 0x191a1b1c 0x1d000102 0x3040506 0x708090c 0xd0e0000 0x242a 0x25292627 0x280a0b0c 0x90d080e 0x00 0x00 0x00 0x00 0x3c0000 0x00 0x00 0x3c303030 0x30303030 0x30303030 0x303c0000 0x00 0x00 0x00 0x00 0x00 0x00 0xcd01>;
				goodix,cfg-group5 = <0x5b580200 0x4053d40 0x2082808 0x463c0305 0x00 0x13330f15 0x15191487 0x27dd6062 0x2a090000 0x9a021d 0x3c6c0000 0x32 0x55 0x6e82e201 0x140a0304 0x88570084 0x5b008060 0x7b6500 0x776b0077 0x00 0x00 0x00 0x200000 0x00 0x00 0x00 0xa0000 0x4000110f 0xf101112 0x13161718 0x191a1b1c 0x1d000102 0x3040506 0x708090c 0xd0e0000 0x242a 0x25292627 0x280a0b0c 0x90d080e 0x00 0x00 0x00 0x00 0x3c0000 0x00 0x00 0x3c303030 0x30303030 0x30303030 0x303c0000 0x00 0x00 0x00 0x00 0x00 0x00 0xcd01>;
			};
		};

		spi@1100a000 {
			compatible = "mediatek,mt8163-spi";
			#address-cells = <0x01>;
			#size-cells = <0x00>;
			reg = <0x00 0x1100a000 0x00 0x1000>;
			interrupts = <0x00 0x76 0x08>;
			clocks = <0x0d 0x29 0x0d 0x49 0x0c 0x1b 0x0c 0x41>;
			clock-names = "parent-clk\0sel-clk\0spi-clk\0dcm-sel-clk";
			pinctrl-names = "default";
			pinctrl-0 = <0x1e>;
			status = "okay";
			mediatek,pad-select = <0x00>;
			linux,phandle = <0x96>;
			phandle = <0x96>;

			audio-codec@0 {
				compatible = "realtek,rt551x";
				reg = <0x00>;
				spi-max-frequency = <0x112a880>;
				linux,phandle = <0x97>;
				phandle = <0x97>;
			};
		};

		thermal@1100b000 {
			compatible = "mediatek,mt8163-thermal";
			reg = <0x00 0x1100b000 0x00 0x1000>;
			interrupts = <0x00 0x4e 0x08>;
			clocks = <0x0c 0x0a 0x0c 0x21>;
			clock-names = "therm\0auxadc";
			apmixedsys = <0x1f>;
			linux,phandle = <0x98>;
			phandle = <0x98>;
		};

		thermal-sensor {
			compatible = "generic-adc-thermal";
			#thermal-sensor-cells = <0x00>;
			io-channels = <0x20 0x00 0x20 0x0e 0x20 0x0f>;
			io-channel-names = "sensor-channel";
			linux,phandle = <0x99>;
			phandle = <0x99>;
		};

		ptp_od@1100b000 {
			compatible = "mediatek,mt8163-ptp_od";
			reg = <0x00 0x1100b000 0x00 0x1000>;
			interrupts = <0x00 0x7d 0x08>;
			clocks = <0x0c 0x0a>;
			clock-names = "ptp_infra_therm";
			linux,phandle = <0x9a>;
			phandle = <0x9a>;
		};

		btif@1100c000 {
			compatible = "mediatek,btif";
			reg = <0x00 0x1100c000 0x00 0x1000 0x00 0x11000700 0x00 0x80 0x00 0x11000780 0x00 0x80>;
			interrupts = <0x00 0x70 0x08 0x00 0x6e 0x08 0x00 0x6f 0x08>;
			clocks = <0x0c 0x1a 0x0c 0x29>;
			clock-names = "btifc\0apdmac";
			linux,phandle = <0x9b>;
			phandle = <0x9b>;
		};

		nfi@1100d000 {
			compatible = "mediatek,mt8163-nfi";
			reg = <0x00 0x1100d000 0x00 0x1000>;
			interrupts = <0x00 0x60 0x08>;
			clocks = <0x0c 0x32 0x0c 0x28 0x0c 0x27 0x0d 0x5d 0x21 0x0d 0x26 0x0d 0x21 0x0c 0x45 0x0d 0x40 0x0c 0x3c 0x0c 0x18 0x0c 0x19 0x0c 0x33>;
			clock-names = "nfi_hclk\0nfiecc_bclk\0nfi_bclk\0onfi_sel\0onfi_clk26m\0onfi_mode5\0onfi_mode4\0nfi_bclk_sel\0nfi_ahb_clk\0nfi_1xpad_clk\0nfiecc_pclk\0nfi_pclk\0onfi_pad_clk";
			linux,phandle = <0x9c>;
			phandle = <0x9c>;
		};

		nfiecc@1100e000 {
			compatible = "mediatek,mt8163-nfiecc";
			reg = <0x00 0x1100e000 0x00 0x1000>;
			interrupts = <0x00 0x5f 0x08>;
			linux,phandle = <0x9d>;
			phandle = <0x9d>;
		};

		usb@11200000 {
			compatible = "mediatek,mt8163-usb20";
			reg = <0x00 0x11200000 0x00 0x10000 0x00 0x11210000 0x00 0x10000>;
			interrupts = <0x00 0x48 0x08>;
			mode = <0x02>;
			multipoint = <0x01>;
			dyn_fifo = <0x01>;
			soft_con = <0x01>;
			dma = <0x01>;
			num_eps = <0x10>;
			dma_channels = <0x08>;
			clocks = <0x1f 0x02 0x0c 0x17 0x0c 0x07>;
			clock-names = "usbpll\0usbmcu\0usb";
			vusb-supply = <0x22>;
			pinctrl-names = "iddig_irq_init\0iddig_irq_low\0iddig_irq_high";
			pinctrl-0 = <0x23>;
			pinctrl-1 = <0x24>;
			pinctrl-2 = <0x25>;
			iddig_gpio = <0x10 0x26 0x00>;
			status = "okay";
			linux,phandle = <0x9e>;
			phandle = <0x9e>;
		};

		audiosys@11220000 {
			compatible = "mediatek,mt8163-audiosys\0syscon";
			reg = <0x00 0x11220000 0x00 0x1000>;
			#clock-cells = <0x01>;
			channel-type = <0x00>;
			switch-mode-delay = <0x01>;
			sound-dai = <0x26>;
			linux,phandle = <0x9f>;
			phandle = <0x9f>;
		};

		mt_soc_dl1_pcm@11220000 {
			compatible = "mediatek,mt8163-soc-pcm-dl1";
			reg = <0x00 0x11220000 0x00 0x1000 0x00 0x11221000 0x00 0x9000>;
			interrupts = <0x00 0x8e 0x08>;
			clocks = <0x0c 0x30 0x0d 0x4f 0x0d 0x50 0x0d 0x57 0x0d 0x58 0x0d 0x0a 0x0d 0x0b 0x21>;
			clock-names = "aud_infra_clk\0top_mux_audio\0top_mux_audio_intbus\0aud_mux1_clk\0aud_mux2_clk\0top_apll1_clk\0top_apll2_clk\0top_clk26m_clk";
			power-domains = <0x27 0x05>;
			pinctrl-names = "default\0audpmicclk-mode0\0audpmicclk-mode1";
			pinctrl-0 = <0x28>;
			pinctrl-1 = <0x29>;
			pinctrl-2 = <0x2a>;
			status = "okay";
			linux,phandle = <0xa0>;
			phandle = <0xa0>;
		};

		mt_soc_ul1_pcm@11220000 {
			compatible = "mediatek,mt8163-soc-pcm-capture";
		};

		mt_soc_voice_md1@11220000 {
			compatible = "mediatek,mt8163-soc-pcm-voice-md1";
		};

		mt_soc_hdmi_pcm@11220000 {
			compatible = "mediatek,mt8163-soc-pcm-hdmi";
		};

		mt_soc_uldlloopback@11220000 {
			compatible = "mediatek,mt8163-soc-pcm-uldlloopback";
		};

		mt_soc_i2s0_pcm@11220000 {
			compatible = "mediatek,mt8163-soc-pcm-dl1-i2s0";
		};

		mt_soc_mrgrx_pcm@11220000 {
			compatible = "mediatek,mt8163-soc-pcm-mrgrx";
		};

		mt_soc_mrgrx_awb_pcm@11220000 {
			compatible = "mediatek,mt8163-soc-pcm-mrgrx-awb";
		};

		mt_soc_fm_i2s_pcm@11220000 {
			compatible = "mediatek,mt8163-soc-pcm-fm-i2s";
		};

		mt_soc_fm_i2s_awb_pcm@11220000 {
			compatible = "mediatek,mt8163-soc-pcm-fm-i2s-awb";
		};

		mt_soc_i2s0dl1_pcm@11220000 {
			compatible = "mediatek,mt8163-soc-pcm-dl1-i2s0Dl1";
		};

		mt_soc_dl1_awb_pcm@11220000 {
			compatible = "mediatek,mt8163-soc-pcm-dl1-awb";
		};

		mt_soc_voice_md1_bt@11220000 {
			compatible = "mediatek,mt8163-soc-pcm-voice-md1-bt";
		};

		mt_soc_voip_bt_out@11220000 {
			compatible = "mediatek,mt8163-soc-pcm-dl1-bt";
		};

		mt_soc_voip_bt_in@11220000 {
			compatible = "mediatek,mt8163-soc-pcm-bt-dai";
		};

		mt_soc_tdmrx_pcm@11220000 {
			compatible = "mediatek,mt8163-soc-tdm-capture";
		};

		mt_soc_fm_mrgtx_pcm@11220000 {
			compatible = "mediatek,mt8163-soc-pcm-fmtx";
		};

		mt_soc_ul2_pcm@11220000 {
			compatible = "mediatek,mt8163-soc-pcm-capture2";
		};

		mt_soc_i2s0_awb_pcm@11220000 {
			compatible = "mediatek,mt8163-soc-pcm-i2s0-awb";
		};

		mt_soc_voice_md2@11220000 {
			compatible = "mediatek,mt8163-soc-pcm-voice-md2";
		};

		mt_soc_routing_pcm@11220000 {
			compatible = "mediatek,mt8163-soc-pcm-routing";
		};

		mt_soc_voice_md2_bt@11220000 {
			compatible = "mediatek,mt8163-soc-pcm-voice-md2-bt";
		};

		mt_soc_hp_impedance@11220000 {
			compatible = "mediatek,mt8163-soc-pcm-hp-impedance";
		};

		mt_soc_codec_name@11220000 {
			compatible = "mediatek,mt8163-soc-codec-63xx";
		};

		mt_soc_dummy_pcm@11220000 {
			compatible = "mediatek,mt8163-soc-pcm-dummy";
		};

		mt_soc_codec_dummy_name@11220000 {
			compatible = "mediatek,mt8163-soc-codec-dummy";
		};

		mt_soc_routing_dai_name@11220000 {
			compatible = "mediatek,mt8163-soc-dai-routing";
		};

		mt_soc_dai_name@11220000 {
			compatible = "mediatek,mt8163-soc-dai-stub";
		};

		mfg@13000000 {
			compatible = "mediatek,mt8163-mfg\0mediatek,midgard-mfg";
			reg = <0x00 0x13000000 0x00 0x1000>;
			clocks = <0x0d 0x46 0x0d 0x18>;
			clock-names = "topck\0pll";
			linux,phandle = <0xa1>;
			phandle = <0xa1>;
		};

		gpu@13040000 {
			compatible = "arm,malit720\0arm,mali-t72x\0arm,malit7xx\0arm,mali-midgard";
			reg = <0x00 0x13040000 0x00 0x4000>;
			interrupts = <0x00 0xe3 0x08 0x00 0xe2 0x08 0x00 0xe1 0x08>;
			interrupt-names = "JOB\0MMU\0GPU";
			clock-frequency = <0x1efe9200>;
			power-domains = <0x27 0x07>;
			linux,phandle = <0xa2>;
			phandle = <0xa2>;
		};

		mmc@11230000 {
			compatible = "mediatek,mt8163-mmc";
			reg = <0x00 0x11230000 0x00 0x1000>;
			interrupts = <0x00 0x4f 0x08>;
			infracfg = <0x0c>;
			clocks = <0x0c 0x1f 0x0c 0x1c>;
			clock-names = "source\0hclk";
			status = "okay";
			pinctrl-names = "default\0state_uhs";
			pinctrl-0 = <0x2b>;
			pinctrl-1 = <0x2c>;
			bus-width = <0x08>;
			mediatek,latch-ck = <0x01>;
			max-frequency = <0xbebc200>;
			cap-mmc-highspeed;
			mmc-hs200-1_8v;
			cap-mmc-hw-reset;
			vmmc-supply = <0x2d>;
			vqmmc-supply = <0x2e>;
			no-sd;
			no-sdio;
			non-removable;
			linux,phandle = <0xa3>;
			phandle = <0xa3>;
		};

		mmc@11240000 {
			compatible = "mediatek,mt8163-mmc";
			reg = <0x00 0x11240000 0x00 0x1000>;
			interrupts = <0x00 0x50 0x08>;
			clocks = <0x0c 0x1d 0x2f>;
			clock-names = "source\0hclk";
			status = "okay";
			pinctrl-names = "default\0state_uhs";
			pinctrl-0 = <0x30>;
			pinctrl-1 = <0x31>;
			bus-width = <0x04>;
			mediatek,latch-ck = <0x01>;
			max-frequency = <0xbebc200>;
			cap-sd-highspeed;
			sd-uhs-sdr50;
			sd-uhs-sdr104;
			cd-gpios = <0x10 0x34 0x00>;
			vmmc-supply = <0x32>;
			vqmmc-supply = <0x33>;
			no-sdio;
			linux,phandle = <0xa4>;
			phandle = <0xa4>;
		};

		mmc@11250000 {
			compatible = "mediatek,mt8163-mmc";
			reg = <0x00 0x11250000 0x00 0x1000>;
			interrupts = <0x00 0x51 0x08>;
			clocks = <0x0c 0x1e 0x2f>;
			clock-names = "source\0hclk";
			status = "disabled";
			linux,phandle = <0xa5>;
			phandle = <0xa5>;
		};

		usb@11270000 {
			compatible = "mediatek,mt8163-usb11";
			cell-index = <0x01>;
			reg = <0x00 0x11270000 0x00 0x10000 0x00 0x11210000 0x00 0x10000>;
			interrupts = <0x00 0x49 0x08>;
			mode = <0x02>;
			multipoint = <0x01>;
			dyn_fifo = <0x01>;
			soft_con = <0x01>;
			dma = <0x01>;
			num_eps = <0x08>;
			dma_channels = <0x04>;
			clocks = <0x1f 0x02 0x0c 0x17 0x0c 0x08>;
			clock-names = "usbpll\0usbmcu\0icusb";
			status = "disabled";
			linux,phandle = <0xa6>;
			phandle = <0xa6>;
		};

		mmsys@14000000 {
			compatible = "mediatek,mt8163-mmsys\0syscon";
			reg = <0x00 0x14000000 0x00 0x1000>;
			#clock-cells = <0x01>;
			linux,phandle = <0x11>;
			phandle = <0x11>;
		};

		mdp_rdma@14001000 {
			compatible = "mediatek,mt8163-mdp_rdma";
			reg = <0x00 0x14001000 0x00 0x1000>;
			interrupts = <0x00 0xb2 0x08>;
			linux,phandle = <0xa7>;
			phandle = <0xa7>;
		};

		mdp_rsz0@14002000 {
			compatible = "mediatek,mt8163-mdp_rsz0";
			reg = <0x00 0x14002000 0x00 0x1000>;
			interrupts = <0x00 0xb3 0x08>;
			linux,phandle = <0xa8>;
			phandle = <0xa8>;
		};

		mdp_rsz1@14003000 {
			compatible = "mediatek,mt8163-mdp_rsz1";
			reg = <0x00 0x14003000 0x00 0x1000>;
			interrupts = <0x00 0xb4 0x08>;
			linux,phandle = <0xa9>;
			phandle = <0xa9>;
		};

		mdp_wdma@14004000 {
			compatible = "mediatek,mt8163-mdp_wdma";
			reg = <0x00 0x14004000 0x00 0x1000>;
			interrupts = <0x00 0xb6 0x08>;
			linux,phandle = <0xaa>;
			phandle = <0xaa>;
		};

		mdp_wrot@14005000 {
			compatible = "mediatek,mt8163-mdp_wrot";
			reg = <0x00 0x14005000 0x00 0x1000>;
			interrupts = <0x00 0xb7 0x08>;
			linux,phandle = <0xab>;
			phandle = <0xab>;
		};

		mdp_tdshp@14006000 {
			compatible = "mediatek,mt8163-mdp_tdshp0";
			reg = <0x00 0x14006000 0x00 0x1000>;
			interrupts = <0x00 0xb5 0x08>;
			linux,phandle = <0xac>;
			phandle = <0xac>;
		};

		mt8163-dispsys {
			compatible = "mediatek,mt8163-dispsys";
			linux,phandle = <0xad>;
			phandle = <0xad>;
		};

		disp_ovl0@14007000 {
			compatible = "mediatek,mt8163-disp_ovl0";
			reg = <0x00 0x14007000 0x00 0x1000>;
			interrupts = <0x00 0xb8 0x08>;
			linux,phandle = <0xae>;
			phandle = <0xae>;
		};

		disp_ovl1@14008000 {
			compatible = "mediatek,mt8163-disp_ovl1";
			reg = <0x00 0x14008000 0x00 0x1000>;
			interrupts = <0x00 0xb9 0x08>;
			linux,phandle = <0xaf>;
			phandle = <0xaf>;
		};

		disp_rdma0@14009000 {
			compatible = "mediatek,mt8163-disp_rdma0";
			reg = <0x00 0x14009000 0x00 0x1000>;
			interrupts = <0x00 0xba 0x08>;
			linux,phandle = <0xb0>;
			phandle = <0xb0>;
		};

		disp_rdma1@1400a000 {
			compatible = "mediatek,mt8163-disp_rdma1";
			reg = <0x00 0x1400a000 0x00 0x1000>;
			interrupts = <0x00 0xbb 0x08>;
			linux,phandle = <0xb1>;
			phandle = <0xb1>;
		};

		disp_wdma0@1400b000 {
			compatible = "mediatek,mt8163-disp_wdma0";
			reg = <0x00 0x1400b000 0x00 0x1000>;
			interrupts = <0x00 0xbc 0x08>;
			linux,phandle = <0xb2>;
			phandle = <0xb2>;
		};

		disp_color@1400c000 {
			compatible = "mediatek,mt8163-disp_color";
			reg = <0x00 0x1400c000 0x00 0x1000>;
			interrupts = <0x00 0xbd 0x08>;
			linux,phandle = <0xb3>;
			phandle = <0xb3>;
		};

		disp_ccorr@1400d000 {
			compatible = "mediatek,mt8163-disp_ccorr";
			reg = <0x00 0x1400d000 0x00 0x1000>;
			interrupts = <0x00 0xbe 0x08>;
			linux,phandle = <0xb4>;
			phandle = <0xb4>;
		};

		disp_aal@1400e000 {
			compatible = "mediatek,mt8163-disp_aal";
			reg = <0x00 0x1400e000 0x00 0x1000>;
			interrupts = <0x00 0xbf 0x08>;
			linux,phandle = <0xb5>;
			phandle = <0xb5>;
		};

		disp_gamma@1400f000 {
			compatible = "mediatek,mt8163-disp_gamma";
			reg = <0x00 0x1400f000 0x00 0x1000>;
			interrupts = <0x00 0xc0 0x08>;
			linux,phandle = <0xb6>;
			phandle = <0xb6>;
		};

		disp_dither@14010000 {
			compatible = "mediatek,mt8163-disp_dither";
			reg = <0x00 0x14010000 0x00 0x1000>;
			interrupts = <0x00 0xc1 0x08>;
			linux,phandle = <0xb7>;
			phandle = <0xb7>;
		};

		disp_ufoe@14011000 {
			compatible = "mediatek,mt8163-disp_ufoe";
			reg = <0x00 0x14011000 0x00 0x1000>;
			linux,phandle = <0xb8>;
			phandle = <0xb8>;
		};

		disp_dsi0@14012000 {
			compatible = "mediatek,mt8163-disp_dsi0";
			reg = <0x00 0x14012000 0x00 0x1000>;
			interrupts = <0x00 0xc3 0x08>;
			linux,phandle = <0xb9>;
			phandle = <0xb9>;
		};

		disp_dpi0@14013000 {
			compatible = "mediatek,mt8163-disp_dpi0";
			reg = <0x00 0x14013000 0x00 0x1000>;
			interrupts = <0x00 0xc4 0x08>;
			linux,phandle = <0xba>;
			phandle = <0xba>;
		};

		disp_dpi1@1401c000 {
			compatible = "mediatek,mt8163-disp_dpi1";
			reg = <0x00 0x1401c000 0x00 0x1000>;
			interrupts = <0x00 0xc9 0x08>;
			linux,phandle = <0xbb>;
			phandle = <0xbb>;
		};

		hdmi@1401d000 {
			compatible = "mediatek,mt8163-hdmitx";
			power-domains = <0x27 0x00>;
			reg = <0x00 0x1401d000 0x00 0x1000 0x00 0x1100f000 0x00 0x10 0x00 0x10013000 0x00 0xbc>;
			interrupts = <0x00 0xca 0x08>;
			clocks = <0x0c 0x25 0x0c 0x26 0x11 0x2a 0x11 0x2d 0x11 0x2c 0x11 0x2b>;
			clock-names = "cec_pdn\0clk_cec_26m\0mmsys_hdmi_pll\0mmsys_hdmi_pixel\0mmsys_hdmi_audio\0mmsys_hdmi_spidif";
			linux,phandle = <0xbc>;
			phandle = <0xbc>;
		};

		disp_pwm0@14014000 {
			compatible = "mediatek,mt8163-disp_pwm";
			reg = <0x00 0x14014000 0x00 0x1000>;
			linux,phandle = <0xbd>;
			phandle = <0xbd>;
		};

		mm_mutex@14015000 {
			compatible = "mediatek,mt8163-disp_mutex";
			reg = <0x00 0x14015000 0x00 0x1000>;
			interrupts = <0x00 0xb1 0x08>;
			linux,phandle = <0xbe>;
			phandle = <0xbe>;
		};

		disp_wdma1@14018000 {
			compatible = "mediatek,mt8163-disp_wdma1";
			reg = <0x00 0x14018000 0x00 0x1000>;
			interrupts = <0x00 0xc6 0x08>;
			linux,phandle = <0xbf>;
			phandle = <0xbf>;
		};

		disp_config2@10206000 {
			compatible = "mediatek,mt8163-disp_config2";
			reg = <0x00 0x10206000 0x00 0x1000>;
			linux,phandle = <0xc0>;
			phandle = <0xc0>;
		};

		disp_config3@10000000 {
			compatible = "mediatek,mt8163-disp_config3";
			reg = <0x00 0x10000000 0x00 0x1000>;
			linux,phandle = <0xc1>;
			phandle = <0xc1>;
		};

		disp_mipi@10215000 {
			compatible = "mediatek,mt8163-disp_mipi";
			reg = <0x00 0x10215000 0x00 0x1000>;
			linux,phandle = <0xc2>;
			phandle = <0xc2>;
		};

		disp_io_driving@10005000 {
			compatible = "mediatek,mt8163-disp_io_driving";
			reg = <0x00 0x10005000 0x00 0x1000>;
			linux,phandle = <0xc3>;
			phandle = <0xc3>;
		};

		disp_tvdpll_cfg6@100000a0 {
			compatible = "mediatek,mt8163-disp_tvdpll_cfg6";
			reg = <0x00 0x100000a0 0x00 0x1000>;
			linux,phandle = <0xc4>;
			phandle = <0xc4>;
		};

		disp_tvdpll_con0@1000c270 {
			compatible = "mediatek,mt8163-disp_tvdpll_con0";
			reg = <0x00 0x1000c270 0x00 0x1000>;
			linux,phandle = <0xc5>;
			phandle = <0xc5>;
		};

		disp_tvdpll_con1@1000c274 {
			compatible = "mediatek,mt8163-disp_tvdpll_con1";
			reg = <0x00 0x1000c274 0x00 0x1000>;
			linux,phandle = <0xc6>;
			phandle = <0xc6>;
		};

		disp_lvds_ana@10215800 {
			compatible = "mediatek,mt8163-disp_lvds_ana";
			reg = <0x00 0x10215800 0x00 0x1000>;
			linux,phandle = <0xc7>;
			phandle = <0xc7>;
		};

		g3d_iommu@13005000 {
			cell-index = <0x02>;
			compatible = "mediatek,mt8163-g3d_iommu";
			reg = <0x00 0x13005000 0x00 0x1000>;
			interrupts = <0x00 0xe2 0x08>;
		};

		larb@14016000 {
			compatible = "mediatek,mt8163-smi-larb";
			reg = <0x00 0x14016000 0x00 0x1000>;
			interrupts = <0x00 0xcd 0x08>;
			mediatek,smi = <0x34>;
			mediatek,larbid = <0x00>;
			clocks = <0x11 0x01 0x11 0x01>;
			clock-names = "apb\0smi";
			power-domains = <0x27 0x00>;
			linux,phandle = <0xc8>;
			phandle = <0xc8>;
		};

		smi@14017000 {
			compatible = "mediatek,mt8163-smi";
			reg = <0x00 0x14017000 0x00 0x1000 0x00 0x14000100 0x00 0x10>;
			reg-names = "\0mmsys_cg_con0_base";
			clocks = <0x11 0x00 0x11 0x00>;
			clock-names = "apb\0smi";
			power-domains = <0x27 0x00>;
			linux,phandle = <0x34>;
			phandle = <0x34>;
		};

		met_smi@14017000 {
			compatible = "mediatek,met_smi";
			reg = <0x00 0x14017000 0x00 0x1000 0x00 0x14016000 0x00 0x1000 0x00 0x16010000 0x00 0x1000 0x00 0x15001000 0x00 0x1000 0x00 0x17001000 0x00 0x1000>;
			clocks = <0x11 0x00 0x11 0x01 0x35 0x00 0x36 0x00 0x37 0x01>;
			clock-names = "smi-common\0smi-larb0\0vdec-larb1\0img-larb2\0venc-larb3";
			linux,phandle = <0xc9>;
			phandle = <0xc9>;
		};

		disp_lvds_tx@1401b200 {
			compatible = "mediatek,mt8163-disp_lvds_tx";
			reg = <0x00 0x1401b200 0x00 0x1000>;
			linux,phandle = <0xca>;
			phandle = <0xca>;
		};

		imgsys@15000000 {
			compatible = "mediatek,mt8163-imgsys\0syscon";
			reg = <0x00 0x15000000 0x00 0x1000>;
			#clock-cells = <0x01>;
			linux,phandle = <0x36>;
			phandle = <0x36>;
		};

		isp_display {
			compatible = "mediatek,mt8163-isp_display";
			linux,phandle = <0xcb>;
			phandle = <0xcb>;
		};

		ispsys@15000000 {
			compatible = "mediatek,mt8163-ispsys";
			reg = <0x00 0x15004000 0x00 0x9000 0x00 0x15000000 0x00 0x10000 0x00 0x10217000 0x00 0x3000>;
			interrupts = <0x00 0xda 0x08 0x00 0xdb 0x08>;
			clocks = <0x36 0x00 0x36 0x02 0x36 0x03 0x36 0x04 0x36 0x05 0x36 0x06 0x11 0x00>;
			clock-names = "IMG_LARB2_SMI\0IMG_CAM_SMI\0IMG_CAM_CAM\0IMG_SEN_TG\0IMG_SEN_CAM\0IMG_CAM_SV\0MM_SMI_COMMON";
			linux,phandle = <0xcc>;
			phandle = <0xcc>;
		};

		larb@15001000 {
			compatible = "mediatek,mt8163-smi-larb";
			reg = <0x00 0x15001000 0x00 0x1000>;
			interrupts = <0x00 0xd9 0x08>;
			mediatek,smi = <0x34>;
			mediatek,larbid = <0x02>;
			clocks = <0x36 0x00 0x36 0x00>;
			clock-names = "apb\0smi";
			power-domains = <0x27 0x03>;
			linux,phandle = <0xcd>;
			phandle = <0xcd>;
		};

		camera1@15008000 {
			compatible = "mediatek,mt8163-camera_hw";
			reg = <0x00 0x15008000 0x00 0x1000>;
			clocks = <0x0d 0x47 0x0d 0x36 0x0d 0x39>;
			clock-names = "TOP_CAMTG_SEL\0TOP_UNIVPLL_D26\0TOP_UNIVPLL2_D2";
			reg-vcama-supply = <0x38>;
			reg-vcamd-supply = <0x39>;
			reg-vcamio-supply = <0x3a>;
			reg-vcamaf-supply = <0x1d>;
			reg-vcami2c-supply = <0x2e>;
			io-channels = <0x20 0x0d>;
			pinctrl-names = "default\0cam0_rst0\0cam0_rst1\0cam0_pnd0\0cam0_pnd1\0cam1_rst0\0cam1_rst1\0cam1_pnd0\0cam1_pnd1\0cam_mclk\0cam0_rdn0\0cam0_rdp0\0cam0_rcn\0cam0_rcp\0cam1_rcn_a\0cam1_rcp_a\0cam1_rdn0_a\0cam1_rdp0_a";
			pinctrl-0 = <0x3b>;
			pinctrl-1 = <0x3c>;
			pinctrl-2 = <0x3d>;
			pinctrl-3 = <0x3e>;
			pinctrl-4 = <0x3f>;
			pinctrl-5 = <0x40>;
			pinctrl-6 = <0x41>;
			pinctrl-7 = <0x42>;
			pinctrl-8 = <0x43>;
			pinctrl-9 = <0x44>;
			pinctrl-10 = <0x45>;
			pinctrl-11 = <0x46>;
			pinctrl-12 = <0x47>;
			pinctrl-13 = <0x48>;
			pinctrl-14 = <0x49>;
			pinctrl-15 = <0x4a>;
			pinctrl-16 = <0x4b>;
			pinctrl-17 = <0x4c>;
			status = "okay";
			linux,phandle = <0xce>;
			phandle = <0xce>;
		};

		camera2@15008000 {
			compatible = "mediatek,mt8163-camera_hw2";
			reg = <0x00 0x15008000 0x00 0x1000>;
			reg-vcama-supply = <0x38>;
			reg-vcamd-supply = <0x4d>;
			reg-vcamio-supply = <0x3a>;
			reg-vcamaf-supply = <0x1d>;
			reg-vcami2c-supply = <0x2e>;
			linux,phandle = <0xcf>;
			phandle = <0xcf>;
		};

		vdecsys@16000000 {
			compatible = "mediatek,mt8163-vdecsys\0syscon";
			reg = <0x00 0x16000000 0x00 0x1000>;
			#clock-cells = <0x01>;
			linux,phandle = <0x35>;
			phandle = <0x35>;
		};

		vdec_gcon@16000000 {
			compatible = "mediatek,mt8163-vdec_gcon";
			reg = <0x00 0x16000000 0x00 0x10000>;
		};

		larb@16010000 {
			compatible = "mediatek,mt8163-smi-larb";
			reg = <0x00 0x16010000 0x00 0x10000>;
			interrupts = <0x00 0xd5 0x08>;
			mediatek,smi = <0x34>;
			mediatek,larbid = <0x01>;
			clocks = <0x35 0x00 0x35 0x01>;
			clock-names = "apb\0smi";
			power-domains = <0x27 0x01>;
			linux,phandle = <0xd0>;
			phandle = <0xd0>;
		};

		vdec@16020000 {
			compatible = "mediatek,mt8163-vdec";
			reg = <0x00 0x16020000 0x00 0x10000>;
			interrupts = <0x00 0xd4 0x08>;
		};

		vencsys@17000000 {
			compatible = "mediatek,mt8163-vencsys\0syscon";
			reg = <0x00 0x17000000 0x00 0x1000>;
			#clock-cells = <0x01>;
			linux,phandle = <0x37>;
			phandle = <0x37>;
		};

		larb@17001000 {
			compatible = "mediatek,mt8163-smi-larb";
			reg = <0x00 0x17001000 0x00 0x1000>;
			interrupts = <0x00 0xcf 0x08>;
			mediatek,smi = <0x34>;
			mediatek,larbid = <0x03>;
			clocks = <0x37 0x01 0x37 0x00>;
			clock-names = "apb\0smi";
			power-domains = <0x27 0x02>;
			linux,phandle = <0xd1>;
			phandle = <0xd1>;
		};

		venc@17002000 {
			compatible = "mediatek,mt8163-venc";
			reg = <0x00 0x17002000 0x00 0x1000>;
			interrupts = <0x00 0xce 0x08>;
		};

		jpgenc@17003000 {
			compatible = "mediatek,mt8163-jpgenc\0mediatek,venc_jpg";
			reg = <0x00 0x17003000 0x00 0x1000>;
			interrupts = <0x00 0xd0 0x08>;
			clocks = <0x37 0x02>;
			clock-names = "venc-jpgenc";
		};

		btcvsd@18000000 {
			compatible = "mediatek,mt8163-audio_bt_cvsd\0mediatek,audio_bt_cvsd";
			offset = <0xf00 0x800 0xfd0 0xfd4 0xfd8>;
			reg = <0x00 0x10001000 0x00 0x1000 0x00 0x18000000 0x00 0x10000 0x00 0x18080000 0x00 0x8000>;
			interrupts = <0x00 0xec 0x08>;
		};

		consys@18070000 {
			compatible = "mediatek,mt8163-consys";
			reg = <0x00 0x18070000 0x00 0x200 0x00 0x10001000 0x00 0x1000 0x00 0x10007000 0x00 0x100>;
			power-domains = <0x27 0x04>;
			interrupts = <0x00 0xed 0x08 0x00 0xec 0x08>;
			resets = <0x4e 0x0c>;
			reset-names = "connsys";
			status = "okay";
			pinctrl-names = "default\0gps_lna_state_init\0gps_lna_state_oh\0gps_lna_state_ol\0wifi_reset_init";
			pinctrl-0 = <0x4f>;
			pinctrl-1 = <0x50>;
			pinctrl-2 = <0x51>;
			pinctrl-3 = <0x52>;
			pinctrl-4 = <0x53>;
			vcn18-supply = <0x54>;
			vcn28-supply = <0x55>;
			vcn33_bt-supply = <0x56>;
			vcn33_wifi-supply = <0x57>;
			linux,phandle = <0xd2>;
			phandle = <0xd2>;
		};

		wifi@180f0000 {
			compatible = "mediatek,wifi";
			reg = <0x00 0x180f0000 0x00 0x5c>;
			interrupts = <0x00 0xee 0x08>;
			clocks = <0x0c 0x29>;
			clock-names = "wifi-dma";
		};

		accdet@ {
			compatible = "mediatek,mt8163-accdet";
			status = "okay";
			interrupt-parent = <0x10>;
			interrupts = <0x04 0x08>;
			eint-debounce = <0x3e800>;
			accdet-gpio = <0x10 0x1a 0x00>;
			hp-sw1-pin = <0x10 0x5a 0x01>;
			hp-sw2-pin = <0x10 0x57 0x00>;
			mic_dangling_vol = <0x672>;
			mic_voltage_delay = <0x50>;
			switch-mode-vol = <0x226>;
			switch-mode-delay = <0x1f4>;
			accdet-mic-vol = <0x07>;
			headset-mode-setting = <0x500 0x500 0x01 0x1f0 0x800 0x800 0x4000>;
			accdet-plugout-debounce = <0x3e8>;
			accdet-mic-mode = <0x01>;
			accdet-micbias1-ind-ctl = <0x01>;
			headset-three-key-threshold = <0x00 0x64 0xdc 0x1f4>;
			headset-four-key-threshold = <0x00 0x3a 0x79 0xc0 0x1c2>;
			pinctrl-names = "default\0state_eint_as_int";
			pinctrl-0 = <0x58>;
			pinctrl-1 = <0x59>;
			linux,phandle = <0xd3>;
			phandle = <0xd3>;
		};

		touch@ {
			compatible = "mediatek,mt8163-touch";
			vtouch-supply = <0x1c>;
			tpd-resolution = <0x2d0 0x500>;
			use-tpd-button = <0x00>;
			tpd-key-num = <0x04>;
			tpd-key-local = <0x8b 0xac 0x9e 0x00>;
			tpd-key-dim-local = <0x3c 0x352 0x32 0x1e 0xb4 0x352 0x32 0x1e 0x12c 0x352 0x32 0x1e 0x1a4 0x352 0x32 0x1e>;
			tpd-max-touch-num = <0x05>;
			tpd-filter-enable = <0x01>;
			tpd-filter-pixel-density = <0x7c>;
			tpd-filter-custom-prameters = <0x00 0x00 0x00 0x00 0x00 0x00 0x00 0x00 0x00 0x00 0x00 0x00>;
			tpd-filter-custom-speed = <0x00 0x00 0x00>;
			pinctrl-names = "default\0state_eint_as_int\0state_eint_output0\0state_eint_output1\0state_rst_output0\0state_rst_output1";
			pinctrl-0 = <0x5a>;
			pinctrl-1 = <0x1b>;
			pinctrl-2 = <0x1a>;
			pinctrl-3 = <0x5b>;
			pinctrl-4 = <0x5c>;
			pinctrl-5 = <0x5d>;
			status = "okay";
			linux,phandle = <0xd4>;
			phandle = <0xd4>;
		};

		gps {
			compatible = "mediatek,gps";
		};

		hwmsensor@0 {
			compatible = "mediatek,hwmsensor";
		};

		gsensor@0 {
			compatible = "mediatek,gsensor";
		};

		als_ps@0 {
			compatible = "mediatek,als_ps";
			pinctrl-names = "pin_default\0pin_cfg";
			pinctrl-0 = <0x5e>;
			pinctrl-1 = <0x5f>;
			status = "okay";
			linux,phandle = <0xd5>;
			phandle = <0xd5>;
		};

		batchsensor@0 {
			compatible = "mediatek,batchsensor";
		};

		gyroscope@0 {
			compatible = "mediatek,gyroscope";
			linux,phandle = <0xd6>;
			phandle = <0xd6>;
		};

		barometer@0 {
			compatible = "mediatek,barometer";
		};

		msensor@0 {
			compatible = "mediatek,msensor";
		};

		orientation@0 {
			compatible = "mediatek,orientation";
		};

		led@0 {
			compatible = "mediatek,red";
			led_mode = <0x00>;
			data;
			pwm_config = <0x00 0x00 0x00 0x00 0x00>;
			linux,phandle = <0xd7>;
			phandle = <0xd7>;
		};

		led@1 {
			compatible = "mediatek,green";
			led_mode = <0x00>;
			data;
			pwm_config = <0x00 0x00 0x00 0x00 0x00>;
			linux,phandle = <0xd8>;
			phandle = <0xd8>;
		};

		led@2 {
			compatible = "mediatek,blue";
			led_mode = <0x00>;
			data;
			pwm_config = <0x00 0x00 0x00 0x00 0x00>;
			linux,phandle = <0xd9>;
			phandle = <0xd9>;
		};

		led@3 {
			compatible = "mediatek,jogball-backlight";
			led_mode = <0x00>;
			data;
			pwm_config = <0x00 0x00 0x00 0x00 0x00>;
			linux,phandle = <0xda>;
			phandle = <0xda>;
		};

		led@4 {
			compatible = "mediatek,keyboard-backlight";
			led_mode = <0x00>;
			data;
			pwm_config = <0x00 0x00 0x00 0x00 0x00>;
			linux,phandle = <0xdb>;
			phandle = <0xdb>;
		};

		led@5 {
			compatible = "mediatek,button-backlight";
			led_mode = <0x00>;
			data;
			pwm_config = <0x00 0x00 0x00 0x00 0x00>;
			linux,phandle = <0xdc>;
			phandle = <0xdc>;
		};

		led@6 {
			compatible = "mediatek,lcd-backlight";
			led_mode = <0x05>;
			data;
			pwm_config = <0x00 0x00 0x00 0x00 0x00>;
			gpios = <0x10 0x2b 0x00>;
			linux,phandle = <0xdd>;
			phandle = <0xdd>;
		};

		mtkfb@0 {
			compatible = "mediatek,MTKFB";
			clocks = <0x11 0x09 0x11 0x0a 0x11 0x0b 0x11 0x0c 0x11 0x0d 0x11 0x0e 0x11 0x17 0x11 0x0f 0x11 0x10 0x11 0x11 0x11 0x12 0x11 0x13 0x11 0x14 0x11 0x20 0x11 0x21 0x11 0x22 0x11 0x23 0x11 0x24 0x11 0x25 0x11 0x26 0x11 0x27 0x11 0x28 0x11 0x29 0x11 0x2e 0x11 0x2f 0x0d 0x55 0x1f 0x0a 0x0d 0x14 0x0d 0x15 0x0d 0x16 0x0d 0x59 0x1f 0x06 0x0d 0x2d 0x0d 0x2e 0x0d 0x2f 0x0d 0x30 0x0d 0x44>;
			clock-names = "MMSYS_CLK_FAKE_ENG\0MMSYS_CLK_DISP_OVL0\0MMSYS_CLK_DISP_OVL1\0MMSYS_CLK_DISP_RDMA0\0MMSYS_CLK_DISP_RDMA1\0MMSYS_CLK_DISP_WDMA0\0MMSYS_CLK_DISP_WDMA1\0MMSYS_CLK_DISP_COLOR\0MMSYS_CLK_DISP_CCORR\0MMSYS_CLK_DISP_AAL\0MMSYS_CLK_DISP_GAMMA\0MMSYS_CLK_DISP_DITHER\0MMSYS_CLK_DISP_UFOE\0MMSYS_CLK_DISP_PWM\0MMSYS_CLK_DISP_PWM26M\0MMSYS_CLK_DSI_ENGINE\0MMSYS_CLK_DSI_DIGITAL\0MMSYS_CLK_DPI0_PIXEL\0MMSYS_CLK_DPI0_ENGINE\0MMSYS_CLK_LVDS_PIXEL\0MMSYS_CLK_LVDS_CTS\0MMSYS_CLK_DPI1_PIXEL\0MMSYS_CLK_DPI1_ENGINE\0MMSYS_CLK_DISP_DSC_ENGINE\0MMSYS_CLK_DISP_DSC_MEM\0MMSYS_CLK_MUX_DPI0_SEL\0MMSYS_APMIXED_LVDSPLL\0MMSYS_CLK_MUX_LVDSPLL_D2\0MMSYS_CLK_MUX_LVDSPLL_D4\0MMSYS_CLK_MUX_LVDSPLL_D8\0MMSYS_CLK_MUX_DPI1_SEL\0MMSYS_APMIXED_TVDPLL\0MMSYS_CLK_MUX_TVDPLL_D2\0MMSYS_CLK_MUX_TVDPLL_D4\0MMSYS_CLK_MUX_TVDPLL_D8\0MMSYS_CLK_MUX_TVDPLL_D16\0MMSYS_CLK_PWM_SEL";
			linux,phandle = <0xde>;
			phandle = <0xde>;
		};

		bat_meter {
			compatible = "mediatek,bat_meter";
			vbat_channel_number = <0x06>;
			isense_channel_number = <0x07>;
			vbattemp_channel_number = <0x05>;
			vcharger_channel_number = <0x04>;
			swchr_power_path = <0x01>;
			external_swchr_support = <0x01>;
			vbat_internal_charging = <0x07>;
			isense_internal_charging = <0x06>;
			r_bat_sense = <0x04>;
			r_i_sense = <0x04>;
			r_charger_1 = <0x14a>;
			r_charger_2 = <0x27>;
			temperature_t0 = <0x6e>;
			temperature_t1 = <0x00>;
			temperature_t1_5 = <0x0a>;
			temperature_t2 = <0x19>;
			temperature_t3 = <0x32>;
			temperature_t = <0xff>;
			fg_meter_resistance = <0x00>;
			oam_d5 = <0x00>;
			change_tracking_point = <0x01>;
			cust_tracking_point = <0x0e>;
			cust_r_sense = <0xc8>;
			cust_hw_cc = <0x00>;
			aging_tuning_value = <0x64>;
			cust_r_fg_offset = <0x00>;
			ocv_board_compesate = <0x00>;
			r_fg_board_base = <0x3e8>;
			r_fg_board_slope = <0x3e8>;
			car_tune_value = <0x64>;
			current_detect_r_fg = <0x0a>;
			minerroroffset = <0x3e8>;
			fg_vbat_average_size = <0x12>;
			r_fg_value = <0x0a>;
			cust_poweron_delta_capacity_tolrance = <0x2d>;
			cust_poweron_low_capacity_tolrance = <0x05>;
			cust_poweron_max_vbat_tolrance = <0x46>;
			cust_poweron_delta_vbat_tolrance = <0x2d>;
			cust_poweron_delta_hw_sw_ocv_capacity_tolrance = <0x0a>;
			fixed_tbat_25 = <0x00>;
			vbat_normal_wakeup = <0xe10>;
			vbat_low_power_wakeup = <0xdac>;
			normal_wakeup_period = <0x1518>;
			low_power_wakeup_period = <0x12c>;
			close_poweroff_wakeup_period = <0x1e>;
			rbat_pull_up_r = <0x4204>;
			rbat_pull_down_r = <0x7530>;
			rbat_pull_up_volt = <0x708>;
			step_of_qmax = <0x3c>;
			slp_current = <0x0d>;
			slp_current_wifi = <0x19>;
			io-channels = <0x20 0x0c>;
			id_volt_max = <0x5c8>;
			id_volt_min = <0x2bc>;
			total_battery_number = <0x02>;
			bat_id_volt_thres = <0x4b0 0xffffffff>;
			batt_temperature_table_num = <0x11>;
			batt_temperature_table = <0xffffffec 0x108ce 0xfffffff1 0xd0d4 0xfffffff6 0xa5d2 0xfffffffb 0x848a 0x00 0x6a90 0x05 0x5636 0x0a 0x4628 0x0f 0x396c 0x14 0x2f3a 0x19 0x2710 0x1e 0x2078 0x23 0x1b1e 0x28 0x16c2 0x2d 0x132f 0x32 0x103e 0x37 0xdd0 0x3c 0xbcb>;
			battery_vendor = "ATL";
			q_max_pos_50 = <0xc54>;
			q_max_pos_25 = <0xc5b>;
			q_max_pos_10 = <0xc5f>;
			q_max_pos_0 = <0xc38>;
			q_max_neg_10 = <0xc36>;
			q_max_pos_50_h_current = <0xc37>;
			q_max_pos_25_h_current = <0xc25>;
			q_max_pos_10_h_current = <0xb88>;
			q_max_pos_0_h_current = <0xb04>;
			q_max_neg_10_h_current = <0x428>;
			q_max_pos_50_500cycle = <0xbf2>;
			q_max_pos_25_500cycle = <0xbe9>;
			q_max_pos_10_500cycle = <0xc09>;
			q_max_pos_0_500cycle = <0xc05>;
			q_max_neg_10_500cycle = <0xb10>;
			q_max_pos_50_h_current_500cycle = <0xbd7>;
			q_max_pos_25_h_current_500cycle = <0xbb5>;
			q_max_pos_10_h_current_500cycle = <0xb15>;
			q_max_pos_0_h_current_500cycle = <0x9a3>;
			q_max_neg_10_h_current_500cycle = <0x4c1>;
			battery_profile_t0_num = <0x3f>;
			battery_profile_t0 = <0x00 0x10e0 0x02 0x10ca 0x03 0x10b5 0x05 0x10a1 0x07 0x108d 0x09 0x1079 0x0a 0x1065 0x0c 0x1052 0x0e 0x103f 0x10 0x102c 0x11 0x1019 0x13 0x1005 0x15 0xff3 0x16 0xfe3 0x18 0xfd0 0x1a 0xfbb 0x1c 0xfa5 0x1d 0xf90 0x1f 0xf7f 0x21 0xf6f 0x23 0xf62 0x24 0xf55 0x26 0xf49 0x28 0xf3d 0x29 0xf32 0x2b 0xf27 0x2d 0xf1d 0x2f 0xf12 0x30 0xf08 0x32 0xf00 0x34 0xef8 0x36 0xef0 0x37 0xee8 0x39 0xee2 0x3b 0xedc 0x3d 0xed5 0x3e 0xed0 0x40 0xeca 0x42 0xec7 0x43 0xec3 0x45 0xebf 0x47 0xebc 0x49 0xeb9 0x4a 0xeb5 0x4c 0xeb2 0x4e 0xead 0x50 0xea8 0x51 0xea3 0x53 0xe9c 0x55 0xe95 0x56 0xe8c 0x58 0xe84 0x5a 0xe7d 0x5c 0xe76 0x5d 0xe70 0x5f 0xe68 0x61 0xe5d 0x62 0xe52 0x62 0xe4c 0x63 0xe45 0x63 0xe3e 0x63 0xe35 0x64 0xe2d>;
			battery_profile_t1_num = <0x3c>;
			battery_profile_t1 = <0x00 0x10d9 0x02 0x10c6 0x03 0x10b3 0x05 0x109f 0x07 0x108c 0x09 0x107a 0x0a 0x1066 0x0c 0x1054 0x0e 0x1042 0x0f 0x1032 0x11 0x101f 0x13 0x100c 0x15 0xffb 0x16 0xfed 0x18 0xfde 0x1a 0xfcb 0x1c 0xfb6 0x1d 0xfa2 0x1f 0xf8f 0x21 0xf7e 0x22 0xf6c 0x24 0xf5e 0x26 0xf51 0x28 0xf45 0x29 0xf37 0x2b 0xf2b 0x2d 0xf20 0x2e 0xf16 0x30 0xf0d 0x32 0xf03 0x34 0xefc 0x35 0xef4 0x37 0xeee 0x39 0xee6 0x3a 0xee0 0x3c 0xeda 0x3e 0xed5 0x40 0xed0 0x41 0xeca 0x43 0xec6 0x45 0xec3 0x47 0xec0 0x48 0xebe 0x4a 0xebb 0x4c 0xeb7 0x4d 0xeb5 0x4f 0xeb0 0x51 0xeaa 0x53 0xea4 0x54 0xe9c 0x56 0xe93 0x58 0xe88 0x59 0xe7d 0x5b 0xe72 0x5d 0xe6d 0x5f 0xe68 0x60 0xe62 0x62 0xe53 0x64 0xe1a 0x64 0xd02>;
			battery_profile_t1_5_num = <0x3d>;
			battery_profile_t1_5 = <0x00 0x10dd 0x02 0x10c9 0x03 0x10b5 0x05 0x10a2 0x07 0x108f 0x09 0x107b 0x0a 0x1069 0x0c 0x1056 0x0e 0x1045 0x0f 0x1032 0x11 0x1021 0x13 0x100f 0x14 0xffe 0x16 0xfee 0x18 0xfe0 0x1a 0xfce 0x1b 0xfbb 0x1d 0xfab 0x1f 0xf9a 0x20 0xf8c 0x22 0xf7f 0x24 0xf71 0x25 0xf61 0x27 0xf4e 0x29 0xf3d 0x2b 0xf2f 0x2c 0xf22 0x2e 0xf18 0x30 0xf0f 0x31 0xf05 0x33 0xefd 0x35 0xef6 0x36 0xeef 0x38 0xee9 0x3a 0xee2 0x3c 0xedd 0x3d 0xed7 0x3f 0xed2 0x41 0xecd 0x42 0xeca 0x44 0xec6 0x46 0xec2 0x48 0xebf 0x49 0xebc 0x4b 0xeb8 0x4d 0xeb4 0x4e 0xeaf 0x50 0xea8 0x52 0xea2 0x53 0xe99 0x55 0xe8f 0x57 0xe85 0x59 0xe77 0x5a 0xe6e 0x5c 0xe6a 0x5e 0xe67 0x5f 0xe60 0x61 0xe4a 0x63 0xdfe 0x64 0xda6 0x65 0xd79>;
			battery_profile_t2_num = <0x3c>;
			battery_profile_t2 = <0x00 0x10db 0x02 0x10c8 0x03 0x10b5 0x05 0x10a1 0x07 0x108f 0x09 0x107c 0x0a 0x1069 0x0c 0x1056 0x0e 0x1044 0x0f 0x1032 0x11 0x1020 0x13 0x100f 0x14 0xffe 0x16 0xfee 0x18 0xfe0 0x1a 0xfce 0x1b 0xfbe 0x1d 0xfad 0x1f 0xf9e 0x20 0xf90 0x22 0xf85 0x24 0xf78 0x26 0xf6a 0x27 0xf57 0x29 0xf41 0x2b 0xf31 0x2c 0xf23 0x2e 0xf19 0x30 0xf11 0x31 0xf07 0x33 0xeff 0x35 0xef8 0x37 0xef0 0x38 0xeea 0x3a 0xee4 0x3c 0xedf 0x3d 0xed9 0x3f 0xed4 0x41 0xecf 0x43 0xecb 0x44 0xec7 0x46 0xec4 0x48 0xebf 0x49 0xeb9 0x4b 0xeb5 0x4d 0xeaf 0x4e 0xea8 0x50 0xea2 0x52 0xe9b 0x54 0xe93 0x55 0xe89 0x57 0xe80 0x59 0xe72 0x5a 0xe6c 0x5c 0xe69 0x5e 0xe66 0x60 0xe62 0x61 0xe45 0x63 0xdf8 0x65 0xd7b>;
			battery_profile_t3_num = <0x3c>;
			battery_profile_t3 = <0x00 0x10db 0x02 0x10c8 0x03 0x10b6 0x05 0x10a3 0x07 0x1090 0x09 0x107d 0x0a 0x106b 0x0c 0x1058 0x0e 0x1046 0x0f 0x1034 0x11 0x1022 0x13 0x1011 0x14 0x1000 0x16 0xff0 0x18 0xfde 0x1a 0xfd0 0x1b 0xfc0 0x1d 0xfb1 0x1f 0xfa3 0x20 0xf95 0x22 0xf88 0x24 0xf7b 0x26 0xf6d 0x27 0xf5e 0x29 0xf48 0x2b 0xf36 0x2c 0xf29 0x2e 0xf1e 0x30 0xf15 0x32 0xf0c 0x33 0xf04 0x35 0xefc 0x37 0xef4 0x38 0xeed 0x3a 0xee7 0x3c 0xee1 0x3d 0xedb 0x3f 0xed6 0x41 0xed0 0x43 0xecd 0x44 0xec8 0x46 0xec3 0x48 0xeb8 0x49 0xeae 0x4b 0xea8 0x4d 0xea2 0x4f 0xe9c 0x50 0xe95 0x52 0xe8f 0x54 0xe87 0x55 0xe7c 0x57 0xe73 0x59 0xe66 0x5b 0xe60 0x5c 0xe5f 0x5e 0xe5d 0x60 0xe57 0x61 0xe38 0x63 0xdec 0x65 0xd77>;
			r_profile_t0_num = <0x3f>;
			r_profile_t0 = <0x341 0x10e0 0x341 0x10ca 0x343 0x10b5 0x340 0x10a1 0x33c 0x108d 0x336 0x1079 0x32f 0x1065 0x32a 0x1052 0x323 0x103f 0x31d 0x102c 0x316 0x1019 0x30c 0x1005 0x309 0xff3 0x304 0xfe3 0x2ff 0xfd0 0x2f8 0xfbb 0x2ec 0xfa5 0x2e7 0xf90 0x2e2 0xf7f 0x2e1 0xf6f 0x2e1 0xf62 0x2df 0xf55 0x2df 0xf49 0x2df 0xf3d 0x2dd 0xf32 0x2dd 0xf27 0x2df 0xf1d 0x2e2 0xf12 0x2e2 0xf08 0x2e9 0xf00 0x2ec 0xef8 0x2f1 0xef0 0x2f3 0xee8 0x2fa 0xee2 0x300 0xedc 0x302 0xed5 0x309 0xed0 0x30c 0xeca 0x313 0xec7 0x319 0xec3 0x322 0xebf 0x32a 0xebc 0x336 0xeb9 0x343 0xeb5 0x355 0xeb2 0x363 0xead 0x378 0xea8 0x393 0xea3 0x3b3 0xe9c 0x3d9 0xe95 0x40b 0xe8c 0x453 0xe84 0x4ae 0xe7d 0x523 0xe76 0x599 0xe70 0x613 0xe68 0x6de 0xe5d 0x797 0xe52 0x78d 0xe4c 0x783 0xe45 0x776 0xe3e 0x769 0xe35 0x75b 0xe2d>;
			r_profile_t1_num = <0x3c>;
			r_profile_t1 = <0x151 0x10d9 0x151 0x10c6 0x14f 0x10b3 0x156 0x109f 0x158 0x108c 0x15c 0x107a 0x155 0x1066 0x155 0x1054 0x155 0x1042 0x156 0x1032 0x154 0x101f 0x153 0x100c 0x154 0xffb 0x155 0xfed 0x156 0xfde 0x157 0xfcb 0x150 0xfb6 0x14f 0xfa2 0x14b 0xf8f 0x146 0xf7e 0x13b 0xf6c 0x138 0xf5e 0x134 0xf51 0x136 0xf45 0x131 0xf37 0x130 0xf2b 0x133 0xf20 0x132 0xf16 0x137 0xf0d 0x134 0xf03 0x139 0xefc 0x136 0xef4 0x123 0xeee 0x147 0xee6 0x149 0xee0 0x150 0xeda 0x155 0xed5 0x157 0xed0 0x15c 0xeca 0x15e 0xec6 0x163 0xec3 0x167 0xec0 0x16e 0xebe 0x170 0xebb 0x177 0xeb7 0x183 0xeb5 0x18c 0xeb0 0x195 0xeaa 0x1a2 0xea4 0x1b0 0xe9c 0x1be 0xe93 0x1d5 0xe88 0x1f2 0xe7d 0x21a 0xe72 0x260 0xe6d 0x2cc 0xe68 0x3a1 0xe62 0x4f0 0xe53 0x6af 0xe1a 0x4cf 0xd02>;
			r_profile_t1_5_num = <0x3d>;
			r_profile_t1_5 = <0xc6 0x10dd 0xc6 0x10c9 0xc8 0x10b5 0xcb 0x10a2 0xcb 0x108f 0xca 0x107b 0xcf 0x1069 0xcf 0x1056 0xd2 0x1045 0xd4 0x1032 0xd7 0x1021 0xd9 0x100f 0xd7 0xffe 0xda 0xfee 0xde 0xfe0 0xdf 0xfce 0xdf 0xfbb 0xe3 0xfab 0xe1 0xf9a 0xe1 0xf8c 0xe3 0xf7f 0xde 0xf71 0xd9 0xf61 0xcd 0xf4e 0xc5 0xf3d 0xc1 0xf2f 0xbe 0xf22 0xbe 0xf18 0xc0 0xf0f 0xbe 0xf05 0xc0 0xefd 0xc3 0xef6 0xc6 0xeef 0xc6 0xee9 0xc8 0xee2 0xcb 0xedd 0xcd 0xed7 0xd0 0xed2 0xd2 0xecd 0xd5 0xeca 0xd5 0xec6 0xd5 0xec2 0xd9 0xebf 0xd9 0xebc 0xda 0xeb8 0xde 0xeb4 0xdf 0xeaf 0xdf 0xea8 0xe4 0xea2 0xe9 0xe99 0xee 0xe8f 0xf7 0xe85 0xfc 0xe77 0x109 0xe6e 0x11d 0xe6a 0x143 0xe67 0x184 0xe60 0x1fb 0xe4a 0x348 0xdfe 0x52b 0xda6 0x4e0 0xd79>;
			r_profile_t2_num = <0x3c>;
			r_profile_t2 = <0x75 0x10db 0x75 0x10c8 0x78 0x10b5 0x78 0x10a1 0x7b 0x108f 0x7b 0x107c 0x7d 0x1069 0x7d 0x1056 0x7d 0x1044 0x80 0x1032 0x82 0x1020 0x85 0x100f 0x87 0xffe 0x8a 0xfee 0x8e 0xfe0 0x8c 0xfce 0x91 0xfbe 0x91 0xfad 0x94 0xf9e 0x96 0xf90 0x9b 0xf85 0x99 0xf78 0x98 0xf6a 0x8e 0xf57 0x7f 0xf41 0x78 0xf31 0x73 0xf23 0x73 0xf19 0x76 0xf11 0x75 0xf07 0x75 0xeff 0x76 0xef8 0x75 0xef0 0x78 0xeea 0x7a 0xee4 0x7b 0xedf 0x7d 0xed9 0x7d 0xed4 0x7f 0xecf 0x80 0xecb 0x7f 0xec7 0x82 0xec4 0x80 0xebf 0x7d 0xeb9 0x7d 0xeb5 0x7d 0xeaf 0x7b 0xea8 0x7b 0xea2 0x7d 0xe9b 0x7f 0xe93 0x82 0xe89 0x84 0xe80 0x82 0xe72 0x82 0xe6c 0x89 0xe69 0x94 0xe66 0xa3 0xe62 0xa7 0xe45 0xb6 0xdf8 0xfa 0xd7b>;
			r_profile_t3_num = <0x3c>;
			r_profile_t3 = <0x53 0x10db 0x53 0x10c8 0x55 0x10b6 0x55 0x10a3 0x55 0x1090 0x55 0x107d 0x58 0x106b 0x57 0x1058 0x58 0x1046 0x5a 0x1034 0x5a 0x1022 0x5c 0x1011 0x5d 0x1000 0x61 0xff0 0x61 0xfde 0x62 0xfd0 0x64 0xfc0 0x66 0xfb1 0x67 0xfa3 0x6b 0xf95 0x6c 0xf88 0x70 0xf7b 0x71 0xf6d 0x70 0xf5e 0x62 0xf48 0x5a 0xf36 0x57 0xf29 0x55 0xf1e 0x57 0xf15 0x57 0xf0c 0x58 0xf04 0x58 0xefc 0x58 0xef4 0x5a 0xeed 0x5d 0xee7 0x5d 0xee1 0x5d 0xedb 0x5f 0xed6 0x5f 0xed0 0x62 0xecd 0x62 0xec8 0x62 0xec3 0x5a 0xeb8 0x57 0xeae 0x58 0xea8 0x5a 0xea2 0x58 0xe9c 0x58 0xe95 0x5a 0xe8f 0x5c 0xe87 0x58 0xe7c 0x5c 0xe73 0x58 0xe66 0x57 0xe60 0x5d 0xe5f 0x64 0xe5d 0x69 0xe57 0x64 0xe38 0x69 0xdec 0x75 0xd77>;
			battery_profile_t1_500cycle = <0x00 0x10f2 0x02 0x10d9 0x04 0x10c3 0x05 0x10ae 0x07 0x1099 0x09 0x1085 0x0b 0x1071 0x0c 0x105d 0x0e 0x104a 0x10 0x1037 0x12 0x1025 0x13 0x1013 0x15 0x1002 0x17 0xff1 0x19 0xfe1 0x1a 0xfd0 0x1c 0xfbe 0x1e 0xfad 0x20 0xf9d 0x21 0xf8c 0x23 0xf79 0x25 0xf64 0x27 0xf4f 0x28 0xf3e 0x2a 0xf31 0x2c 0xf25 0x2e 0xf1a 0x2f 0xf11 0x31 0xf08 0x33 0xeff 0x35 0xef7 0x37 0xef0 0x38 0xee9 0x3a 0xee2 0x3c 0xedc 0x3e 0xed7 0x3f 0xed1 0x41 0xecc 0x43 0xec8 0x45 0xec5 0x46 0xec1 0x48 0xebd 0x4a 0xeb8 0x4c 0xeb3 0x4d 0xeac 0x4f 0xea5 0x51 0xe9e 0x53 0xe94 0x54 0xe8a 0x56 0xe7e 0x58 0xe74 0x5a 0xe6b 0x5b 0xe64 0x5d 0xe5c 0x5f 0xe4d 0x61 0xe23 0x62 0xdd4 0x64 0xd58>;
			battery_profile_t1_5_500cycle = <0x00 0x10e7 0x02 0x10d1 0x04 0x10bd 0x05 0x10a9 0x07 0x1095 0x09 0x1082 0x0b 0x106f 0x0c 0x105c 0x0e 0x1049 0x10 0x1037 0x12 0x1025 0x13 0x1014 0x15 0x1003 0x17 0xff2 0x19 0xfe3 0x1a 0xfd2 0x1c 0xfc2 0x1e 0xfb1 0x20 0xfa0 0x21 0xf90 0x23 0xf7d 0x25 0xf65 0x27 0xf51 0x28 0xf42 0x2a 0xf35 0x2c 0xf2a 0x2e 0xf1f 0x2f 0xf16 0x31 0xf0d 0x33 0xf04 0x35 0xefc 0x36 0xef5 0x38 0xeee 0x3a 0xee7 0x3c 0xee1 0x3d 0xedb 0x3f 0xed5 0x41 0xed0 0x43 0xecb 0x44 0xec5 0x46 0xec0 0x48 0xeba 0x4a 0xeb4 0x4b 0xeae 0x4d 0xea7 0x4f 0xea1 0x51 0xe99 0x52 0xe8f 0x54 0xe85 0x56 0xe79 0x58 0xe6f 0x5a 0xe69 0x5b 0xe64 0x5d 0xe5c 0x5f 0xe41 0x61 0xdfb 0x62 0xd82 0x64 0xd6d>;
			battery_profile_t2_500cycle = <0x00 0x10ed 0x02 0x10d9 0x04 0x10c5 0x05 0x10b2 0x07 0x109f 0x09 0x108c 0x0b 0x1079 0x0c 0x1066 0x0e 0x1053 0x10 0x1041 0x12 0x102f 0x14 0x101d 0x15 0x100c 0x17 0xffb 0x19 0xfea 0x1b 0xfdb 0x1d 0xfcb 0x1e 0xfbb 0x20 0xfab 0x22 0xf9c 0x24 0xf8d 0x25 0xf78 0x27 0xf5e 0x29 0xf4c 0x2b 0xf3e 0x2d 0xf32 0x2e 0xf28 0x30 0xf1e 0x32 0xf15 0x34 0xf0c 0x36 0xf03 0x37 0xefc 0x39 0xef4 0x3b 0xeee 0x3d 0xee7 0x3f 0xee1 0x40 0xedb 0x42 0xed6 0x44 0xed0 0x46 0xeca 0x47 0xec1 0x49 0xeb8 0x4b 0xeb0 0x4d 0xea8 0x4f 0xea1 0x50 0xe9c 0x52 0xe95 0x54 0xe8c 0x56 0xe82 0x58 0xe76 0x59 0xe6b 0x5b 0xe67 0x5d 0xe64 0x5f 0xe60 0x60 0xe50 0x62 0xe10 0x64 0xda4>;
			battery_profile_t3_500cycle = <0x00 0x10e5 0x02 0x10d1 0x04 0x10bd 0x05 0x10aa 0x07 0x1097 0x09 0x1084 0x0b 0x1071 0x0c 0x105e 0x0e 0x104c 0x10 0x103a 0x12 0x1028 0x14 0x1017 0x15 0x1005 0x17 0xff5 0x19 0xfe4 0x1b 0xfd4 0x1d 0xfc5 0x1e 0xfb5 0x20 0xfa7 0x22 0xf99 0x24 0xf8a 0x25 0xf75 0x27 0xf5f 0x29 0xf4d 0x2b 0xf3f 0x2d 0xf33 0x2e 0xf28 0x30 0xf1d 0x32 0xf14 0x34 0xf0b 0x36 0xf02 0x37 0xefb 0x39 0xef3 0x3b 0xeec 0x3d 0xee5 0x3e 0xedf 0x40 0xed9 0x42 0xed4 0x44 0xece 0x46 0xec4 0x47 0xeb8 0x49 0xead 0x4b 0xea4 0x4d 0xe9b 0x4f 0xe93 0x50 0xe8d 0x52 0xe87 0x54 0xe7f 0x56 0xe75 0x57 0xe6a 0x59 0xe5e 0x5b 0xe5a 0x5d 0xe57 0x5f 0xe53 0x60 0xe47 0x62 0xe0e 0x64 0xdae>;
			r_profile_t1_500cycle = <0x1c5 0x10f2 0x1c5 0x10d9 0x1cb 0x10c3 0x1ca 0x10ae 0x1c9 0x1099 0x1ca 0x1085 0x1ca 0x1071 0x1c9 0x105d 0x1c9 0x104a 0x1c7 0x1037 0x1c9 0x1025 0x1c8 0x1013 0x1c8 0x1002 0x1cb 0xff1 0x1cc 0xfe1 0x1ce 0xfd0 0x1cd 0xfbe 0x1cf 0xfad 0x1ce 0xf9d 0x1cc 0xf8c 0x1c7 0xf79 0x1bb 0xf64 0x1b0 0xf4f 0x1aa 0xf3e 0x1a7 0xf31 0x1a7 0xf25 0x1a8 0xf1a 0x1a8 0xf11 0x1ad 0xf08 0x1b2 0xeff 0x1b6 0xef7 0x1bb 0xef0 0x1c1 0xee9 0x1c7 0xee2 0x1cb 0xedc 0x1d1 0xed7 0x1d7 0xed1 0x1dc 0xecc 0x1e2 0xec8 0x1e8 0xec5 0x1ef 0xec1 0x1f8 0xebd 0x204 0xeb8 0x210 0xeb3 0x21e 0xeac 0x22f 0xea5 0x245 0xe9e 0x25f 0xe94 0x280 0xe8a 0x2ac 0xe7e 0x2ec 0xe74 0x349 0xe6b 0x3d0 0xe64 0x48b 0xe5c 0x56b 0xe4d 0x676 0xe23 0x62f 0xdd4 0x1f5 0xd58>;
			r_profile_t1_5_500cycle = <0x10a 0x10e7 0x10a 0x10d1 0x10a 0x10bd 0x10a 0x10a9 0x109 0x1095 0x107 0x1082 0x106 0x106f 0x105 0x105c 0x105 0x1049 0x105 0x1037 0x105 0x1025 0x106 0x1014 0x108 0x1003 0x10a 0xff2 0x10d 0xfe3 0x10f 0xfd2 0x111 0xfc2 0x113 0xfb1 0x114 0xfa0 0x114 0xf90 0x10c 0xf7d 0xfd 0xf65 0xf2 0xf51 0xec 0xf42 0xea 0xf35 0xe9 0xf2a 0xea 0xf1f 0xeb 0xf16 0xee 0xf0d 0xef 0xf04 0xf2 0xefc 0xf5 0xef5 0xf8 0xeee 0xfb 0xee7 0xfe 0xee1 0x101 0xedb 0x104 0xed5 0x107 0xed0 0x109 0xecb 0x10a 0xec5 0x10c 0xec0 0x10c 0xeba 0x10f 0xeb4 0x112 0xeae 0x117 0xea7 0x11e 0xea1 0x126 0xe99 0x12f 0xe8f 0x13a 0xe85 0x145 0xe79 0x158 0xe6f 0x179 0xe69 0x1ab 0xe64 0x1f5 0xe5c 0x25f 0xe41 0x2f4 0xdfb 0x41d 0xd82 0x1b0 0xd6d>;
			r_profile_t2_500cycle = <0x8c 0x10ed 0x8c 0x10d9 0x8d 0x10c5 0x8d 0x10b2 0x8e 0x109f 0x8e 0x108c 0x8f 0x1079 0x8f 0x1066 0x91 0x1053 0x92 0x1041 0x94 0x102f 0x95 0x101d 0x97 0x100c 0x99 0xffb 0x9b 0xfea 0x9e 0xfdb 0xa0 0xfcb 0xa4 0xfbb 0xa7 0xfab 0xac 0xf9c 0xb0 0xf8d 0xa8 0xf78 0x98 0xf5e 0x91 0xf4c 0x8e 0xf3e 0x8d 0xf32 0x8d 0xf28 0x8e 0xf1e 0x8f 0xf15 0x91 0xf0c 0x92 0xf03 0x94 0xefc 0x95 0xef4 0x97 0xeee 0x99 0xee7 0x9a 0xee1 0x9c 0xedb 0x9d 0xed6 0x9e 0xed0 0x9d 0xeca 0x9a 0xec1 0x98 0xeb8 0x98 0xeb0 0x98 0xea8 0x99 0xea1 0x9d 0xe9c 0x9f 0xe95 0xa0 0xe8c 0xa3 0xe82 0xa6 0xe76 0xa4 0xe6b 0xab 0xe67 0xb5 0xe64 0xc4 0xe60 0xd7 0xe50 0xdf 0xe10 0x108 0xda4>;
			r_profile_t3_500cycle = <0x63 0x10e5 0x63 0x10d1 0x64 0x10bd 0x65 0x10aa 0x65 0x1097 0x66 0x1084 0x67 0x1071 0x67 0x105e 0x68 0x104c 0x69 0x103a 0x6a 0x1028 0x6b 0x1017 0x6c 0x1005 0x6e 0xff5 0x6f 0xfe4 0x71 0xfd4 0x72 0xfc5 0x74 0xfb5 0x77 0xfa7 0x7a 0xf99 0x7e 0xf8a 0x7b 0xf75 0x72 0xf5f 0x6d 0xf4d 0x6a 0xf3f 0x69 0xf33 0x69 0xf28 0x69 0xf1d 0x6a 0xf14 0x6a 0xf0b 0x6b 0xf02 0x6d 0xefb 0x6e 0xef3 0x6f 0xeec 0x71 0xee5 0x72 0xedf 0x74 0xed9 0x75 0xed4 0x76 0xece 0x73 0xec4 0x6e 0xeb8 0x6c 0xead 0x6c 0xea4 0x6c 0xe9b 0x6c 0xe93 0x6d 0xe8d 0x6e 0xe87 0x6e 0xe7f 0x6e 0xe75 0x6f 0xe6a 0x6d 0xe5e 0x6f 0xe5a 0x73 0xe57 0x77 0xe53 0x7c 0xe47 0x7a 0xe0e 0x83 0xdae>;
			battery_vendor_1 = "COSLIGHT";
			q_max_pos_50_1 = <0xc18>;
			q_max_pos_25_1 = <0xc0f>;
			q_max_pos_10_1 = <0xc12>;
			q_max_pos_0_1 = <0xcd9>;
			q_max_neg_10_1 = <0xb41>;
			q_max_pos_50_h_current_1 = <0xbe3>;
			q_max_pos_25_h_current_1 = <0xba7>;
			q_max_pos_10_h_current_1 = <0xafb>;
			q_max_pos_0_h_current_1 = <0xb2f>;
			q_max_neg_10_h_current_1 = <0x42f>;
			q_max_pos_50_500cycle_1 = <0xbe9>;
			q_max_pos_25_500cycle_1 = <0xbec>;
			q_max_pos_10_500cycle_1 = <0xbd0>;
			q_max_pos_0_500cycle_1 = <0xbe9>;
			q_max_neg_10_500cycle_1 = <0xaf9>;
			q_max_pos_50_h_current_500cycle_1 = <0xb9e>;
			q_max_pos_25_h_current_500cycle_1 = <0xb6f>;
			q_max_pos_10_h_current_500cycle_1 = <0xae5>;
			q_max_pos_0_h_current_500cycle_1 = <0x87f>;
			q_max_neg_10_h_current_500cycle_1 = <0x410>;
			battery_profile_t0_num_1 = <0x38>;
			battery_profile_t0_1 = <0x00 0x10ea 0x02 0x10c9 0x04 0x10ae 0x05 0x1096 0x07 0x1080 0x09 0x106b 0x0b 0x1057 0x0d 0x1043 0x0f 0x102f 0x10 0x101c 0x12 0x100a 0x14 0xff9 0x16 0xfe8 0x18 0xfd3 0x19 0xfbb 0x1b 0xfa3 0x1d 0xf8d 0x1f 0xf7b 0x21 0xf6b 0x23 0xf5c 0x24 0xf4e 0x26 0xf40 0x28 0xf32 0x2a 0xf25 0x2c 0xf17 0x2d 0xf0b 0x2f 0xeff 0x31 0xef4 0x33 0xeea 0x35 0xee1 0x37 0xed9 0x38 0xed2 0x3a 0xecc 0x3c 0xec6 0x3e 0xec0 0x40 0xebb 0x41 0xeb6 0x43 0xeb0 0x45 0xeaa 0x47 0xea4 0x49 0xe9d 0x4b 0xe96 0x4c 0xe8d 0x4e 0xe84 0x50 0xe7a 0x52 0xe6f 0x54 0xe62 0x55 0xe56 0x57 0xe47 0x59 0xe38 0x5b 0xe28 0x5d 0xe18 0x5f 0xe08 0x60 0xdf9 0x62 0xdea 0x64 0xddb>;
			battery_profile_t1_num_1 = <0x3b>;
			battery_profile_t1_1 = <0x00 0x10e9 0x02 0x10cd 0x03 0x10b5 0x05 0x109f 0x07 0x108b 0x09 0x1077 0x0a 0x1063 0x0c 0x1050 0x0e 0x103e 0x10 0x102b 0x11 0x1019 0x13 0x1007 0x15 0xff6 0x16 0xfe8 0x18 0xfd6 0x1a 0xfbe 0x1c 0xfa5 0x1d 0xf91 0x1f 0xf81 0x21 0xf74 0x22 0xf68 0x24 0xf5b 0x26 0xf4b 0x28 0xf3b 0x29 0xf2c 0x2b 0xf1d 0x2d 0xf10 0x2f 0xf04 0x30 0xef9 0x32 0xeef 0x34 0xee6 0x35 0xedf 0x37 0xed8 0x39 0xed2 0x3b 0xecd 0x3c 0xec9 0x3e 0xec6 0x40 0xec4 0x42 0xec1 0x43 0xebf 0x45 0xebc 0x47 0xeb8 0x48 0xeb4 0x4a 0xeaf 0x4c 0xea8 0x4e 0xea1 0x4f 0xe97 0x51 0xe8c 0x53 0xe7d 0x54 0xe6c 0x56 0xe58 0x58 0xe40 0x5a 0xe29 0x5b 0xe10 0x5d 0xdf6 0x5f 0xde2 0x61 0xdcf 0x62 0xdbd 0x64 0xda4>;
			battery_profile_t1_5_num_1 = <0x3c>;
			battery_profile_t1_5_1 = <0x00 0x10e7 0x02 0x10cb 0x03 0x10b4 0x05 0x109f 0x07 0x108a 0x08 0x1076 0x0a 0x1062 0x0c 0x1050 0x0e 0x103d 0x0f 0x102a 0x11 0x1018 0x13 0x1006 0x14 0xff5 0x16 0xfe8 0x18 0xfd6 0x19 0xfbd 0x1b 0xfa6 0x1d 0xf94 0x1f 0xf86 0x20 0xf7c 0x22 0xf71 0x24 0xf64 0x25 0xf55 0x27 0xf47 0x29 0xf37 0x2a 0xf27 0x2c 0xf17 0x2e 0xf09 0x2f 0xefd 0x31 0xef3 0x33 0xeea 0x35 0xee2 0x36 0xedb 0x38 0xed5 0x3a 0xed0 0x3b 0xecc 0x3d 0xec9 0x3f 0xec7 0x40 0xec6 0x42 0xec5 0x44 0xec4 0x45 0xec2 0x47 0xec0 0x49 0xebd 0x4b 0xeb9 0x4c 0xeb3 0x4e 0xeac 0x50 0xea3 0x51 0xe97 0x53 0xe88 0x55 0xe74 0x56 0xe59 0x58 0xe3c 0x5a 0xe1d 0x5c 0xdfe 0x5d 0xde5 0x5f 0xdd2 0x61 0xdc0 0x62 0xda5 0x64 0xd59>;
			battery_profile_t2_num_1 = <0x3c>;
			battery_profile_t2_1 = <0x00 0x10f1 0x02 0x10d5 0x03 0x10bd 0x05 0x10a7 0x07 0x1092 0x08 0x107e 0x0a 0x1069 0x0c 0x1056 0x0e 0x1043 0x0f 0x1030 0x11 0x101d 0x13 0x100b 0x14 0xff9 0x16 0xfe9 0x18 0xfdb 0x19 0xfc5 0x1b 0xfae 0x1d 0xf9b 0x1f 0xf8e 0x20 0xf84 0x22 0xf76 0x24 0xf68 0x25 0xf5b 0x27 0xf4d 0x29 0xf3f 0x2a 0xf2f 0x2c 0xf1d 0x2e 0xf0c 0x30 0xf00 0x31 0xef5 0x33 0xeec 0x35 0xee4 0x36 0xedd 0x38 0xed7 0x3a 0xed1 0x3b 0xecc 0x3d 0xec8 0x3f 0xec5 0x40 0xec4 0x42 0xec3 0x44 0xec2 0x46 0xec1 0x47 0xebe 0x49 0xebb 0x4b 0xeb7 0x4c 0xeb1 0x4e 0xeab 0x50 0xea3 0x51 0xe9b 0x53 0xe90 0x55 0xe7e 0x57 0xe64 0x58 0xe46 0x5a 0xe23 0x5c 0xe00 0x5d 0xde7 0x5f 0xdd4 0x61 0xdc2 0x62 0xd9a 0x64 0xd42>;
			battery_profile_t3_num_1 = <0x3c>;
			battery_profile_t3_1 = <0x00 0x10e7 0x02 0x10ce 0x03 0x10b7 0x05 0x10a2 0x07 0x108d 0x08 0x1079 0x0a 0x1065 0x0c 0x1052 0x0e 0x103f 0x0f 0x102c 0x11 0x1019 0x13 0x1007 0x14 0xff5 0x16 0xfe3 0x18 0xfd2 0x19 0xfc2 0x1b 0xfb1 0x1d 0xfa2 0x1e 0xf93 0x20 0xf84 0x22 0xf76 0x24 0xf69 0x25 0xf5b 0x27 0xf4e 0x29 0xf41 0x2a 0xf33 0x2c 0xf21 0x2e 0xf0e 0x2f 0xf00 0x31 0xef5 0x33 0xeec 0x34 0xee4 0x36 0xedc 0x38 0xed6 0x3a 0xed0 0x3b 0xeca 0x3d 0xec6 0x3f 0xec2 0x40 0xebe 0x42 0xebc 0x44 0xebb 0x45 0xeba 0x47 0xeb8 0x49 0xeb2 0x4a 0xea7 0x4c 0xea2 0x4e 0xe9c 0x4f 0xe96 0x51 0xe90 0x53 0xe89 0x55 0xe7c 0x56 0xe67 0x58 0xe4e 0x5a 0xe27 0x5b 0xe03 0x5d 0xdeb 0x5f 0xdd8 0x60 0xdc6 0x62 0xda3 0x64 0xd56>;
			r_profile_t0_num_1 = <0x38>;
			r_profile_t0_1 = <0x3dc 0x10ea 0x3dc 0x10c9 0x3d6 0x10ae 0x3cc 0x1096 0x3c3 0x1080 0x3b9 0x106b 0x3b1 0x1057 0x3a9 0x1043 0x3a0 0x102f 0x39a 0x101c 0x395 0x100a 0x391 0xff9 0x38c 0xfe8 0x384 0xfd3 0x378 0xfbb 0x36d 0xfa3 0x364 0xf8d 0x35f 0xf7b 0x35c 0xf6b 0x35a 0xf5c 0x357 0xf4e 0x352 0xf40 0x34d 0xf32 0x34a 0xf25 0x343 0xf17 0x341 0xf0b 0x340 0xeff 0x340 0xef4 0x341 0xeea 0x343 0xee1 0x346 0xed9 0x34b 0xed2 0x352 0xecc 0x357 0xec6 0x35e 0xec0 0x364 0xebb 0x36e 0xeb6 0x375 0xeb0 0x37f 0xeaa 0x387 0xea4 0x391 0xe9d 0x39b 0xe96 0x3a4 0xe8d 0x3af 0xe84 0x3b9 0xe7a 0x3c5 0xe6f 0x3cf 0xe62 0x3dc 0xe56 0x3e8 0xe47 0x3f7 0xe38 0x409 0xe28 0x41f 0xe18 0x43b 0xe08 0x462 0xdf9 0x49c 0xdea 0x4fb 0xddb>;
			r_profile_t1_num_1 = <0x3b>;
			r_profile_t1_1 = <0x1ef 0x10e9 0x1ef 0x10cd 0x1ea 0x10b5 0x1e2 0x109f 0x1dd 0x108b 0x1d6 0x1077 0x1d1 0x1063 0x1cc 0x1050 0x1c9 0x103e 0x1c5 0x102b 0x1c2 0x1019 0x1c0 0x1007 0x1c0 0xff6 0x1c2 0xfe8 0x1c0 0xfd6 0x1b8 0xfbe 0x1b1 0xfa5 0x1b0 0xf91 0x1b1 0xf81 0x1b5 0xf74 0x1b5 0xf68 0x1b3 0xf5b 0x1ab 0xf4b 0x1a6 0xf3b 0x1a1 0xf2c 0x19c 0xf1d 0x19a 0xf10 0x198 0xf04 0x198 0xef9 0x19a 0xeef 0x19a 0xee6 0x19d 0xedf 0x1a1 0xed8 0x1a4 0xed2 0x1a7 0xecd 0x1ac 0xec9 0x1b1 0xec6 0x1ba 0xec4 0x1bf 0xec1 0x1c7 0xebf 0x1ce 0xebc 0x1d3 0xeb8 0x1db 0xeb4 0x1e2 0xeaf 0x1e8 0xea8 0x1ef 0xea1 0x1f6 0xe97 0x1fc 0xe8c 0x200 0xe7d 0x205 0xe6c 0x208 0xe58 0x20a 0xe40 0x20f 0xe29 0x214 0xe10 0x21a 0xdf6 0x22d 0xde2 0x247 0xdcf 0x283 0xdbd 0x30c 0xda4>;
			r_profile_t1_5_num_1 = <0x3c>;
			r_profile_t1_5_1 = <0x11a 0x10e7 0x11a 0x10cb 0x116 0x10b4 0x113 0x109f 0x10e 0x108a 0x10b 0x1076 0x107 0x1062 0x107 0x1050 0x106 0x103d 0x104 0x102a 0x104 0x1018 0x104 0x1006 0x106 0xff5 0x10c 0xfe8 0x10c 0xfd6 0x106 0xfbd 0x104 0xfa6 0x107 0xf94 0x10b 0xf86 0x110 0xf7c 0x110 0xf71 0x10e 0xf64 0x10c 0xf55 0x10c 0xf47 0x107 0xf37 0x102 0xf27 0xfa 0xf17 0xf7 0xf09 0xf3 0xefd 0xf3 0xef3 0xf3 0xeea 0xf3 0xee2 0xf5 0xedb 0xf7 0xed5 0xf8 0xed0 0xfd 0xecc 0x101 0xec9 0x104 0xec7 0x109 0xec6 0x10e 0xec5 0x113 0xec4 0x118 0xec2 0x11b 0xec0 0x120 0xebd 0x125 0xeb9 0x12a 0xeb3 0x131 0xeac 0x136 0xea3 0x13b 0xe97 0x142 0xe88 0x145 0xe74 0x145 0xe59 0x143 0xe3c 0x140 0xe1d 0x140 0xdfe 0x145 0xde5 0x154 0xdd2 0x170 0xdc0 0x1a2 0xda5 0x1fb 0xd59>;
			r_profile_t2_num_1 = <0x3c>;
			r_profile_t2_1 = <0xa3 0x10f1 0xa3 0x10d5 0xa0 0x10bd 0xa0 0x10a7 0xa2 0x1092 0xa2 0x107e 0xa0 0x1069 0xa2 0x1056 0xa3 0x1043 0xa3 0x1030 0xa3 0x101d 0xa7 0x100b 0xa8 0xff9 0xaa 0xfe9 0xb1 0xfdb 0xac 0xfc5 0xaa 0xfae 0xad 0xf9b 0xb2 0xf8e 0xb6 0xf84 0xb4 0xf76 0xb6 0xf68 0xb9 0xf5b 0xb9 0xf4d 0xb9 0xf3f 0xb6 0xf2f 0xad 0xf1d 0xa5 0xf0c 0xa3 0xf00 0xa2 0xef5 0xa2 0xeec 0xa2 0xee4 0xa3 0xedd 0xa5 0xed7 0xa3 0xed1 0xa7 0xecc 0xa8 0xec8 0xaa 0xec5 0xad 0xec4 0xb2 0xec3 0xb4 0xec2 0xb7 0xec1 0xb7 0xebe 0xbb 0xebb 0xbb 0xeb7 0xbb 0xeb1 0xbe 0xeab 0xc0 0xea3 0xc3 0xe9b 0xc8 0xe90 0xcb 0xe7e 0xc8 0xe64 0xc6 0xe46 0xbe 0xe23 0xb9 0xe00 0xb9 0xde7 0xc0 0xdd4 0xcd 0xdc2 0xcf 0xd9a 0xde 0xd42>;
			r_profile_t3_num_1 = <0x3c>;
			r_profile_t3_1 = <0x75 0x10e7 0x75 0x10ce 0x75 0x10b7 0x76 0x10a2 0x76 0x108d 0x76 0x1079 0x76 0x1065 0x76 0x1052 0x76 0x103f 0x78 0x102c 0x76 0x1019 0x78 0x1007 0x78 0xff5 0x7a 0xfe3 0x7a 0xfd2 0x7b 0xfc2 0x7b 0xfb1 0x7d 0xfa2 0x7d 0xf93 0x7f 0xf84 0x80 0xf76 0x82 0xf69 0x84 0xf5b 0x85 0xf4e 0x89 0xf41 0x8a 0xf33 0x85 0xf21 0x7d 0xf0e 0x7a 0xf00 0x7a 0xef5 0x7a 0xeec 0x7a 0xee4 0x7a 0xedc 0x7b 0xed6 0x7b 0xed0 0x7b 0xeca 0x7f 0xec6 0x7f 0xec2 0x7f 0xebe 0x80 0xebc 0x84 0xebb 0x85 0xeba 0x87 0xeb8 0x84 0xeb2 0x7f 0xea7 0x82 0xea2 0x82 0xe9c 0x84 0xe96 0x85 0xe90 0x87 0xe89 0x87 0xe7c 0x89 0xe67 0x8f 0xe4e 0x85 0xe27 0x84 0xe03 0x85 0xdeb 0x89 0xdd8 0x8c 0xdc6 0x8a 0xda3 0x8f 0xd56>;
			battery_profile_t1_500cycle_1 = <0x00 0x10ee 0x02 0x10d1 0x04 0x10b8 0x05 0x10a1 0x07 0x108c 0x09 0x1077 0x0b 0x1063 0x0c 0x1050 0x0e 0x103d 0x10 0x102b 0x12 0x1018 0x13 0x1005 0x15 0xff5 0x17 0xfe6 0x19 0xfd4 0x1b 0xfbc 0x1c 0xfa5 0x1e 0xf92 0x20 0xf82 0x22 0xf75 0x23 0xf68 0x25 0xf59 0x27 0xf45 0x29 0xf31 0x2a 0xf1f 0x2c 0xf10 0x2e 0xf03 0x30 0xef8 0x32 0xeee 0x33 0xee5 0x35 0xedd 0x37 0xed6 0x39 0xecf 0x3a 0xeca 0x3c 0xec6 0x3e 0xec2 0x40 0xebe 0x42 0xebb 0x43 0xeb7 0x45 0xeb3 0x47 0xeae 0x49 0xea8 0x4a 0xea1 0x4c 0xe98 0x4e 0xe8e 0x50 0xe82 0x51 0xe75 0x53 0xe65 0x55 0xe53 0x57 0xe3d 0x59 0xe26 0x5a 0xe0f 0x5c 0xdfa 0x5e 0xde7 0x60 0xdd3 0x61 0xdb7 0x63 0xd76 0x64 0xd31>;
			battery_profile_t1_5_500cycle_1 = <0x00 0x10f0 0x02 0x10d6 0x04 0x10bf 0x05 0x10a9 0x07 0x1094 0x09 0x107f 0x0b 0x106b 0x0c 0x1058 0x0e 0x1045 0x10 0x1032 0x12 0x101f 0x14 0x100d 0x15 0xffb 0x17 0xfec 0x19 0xfde 0x1b 0xfc8 0x1d 0xfb0 0x1e 0xf9b 0x20 0xf8c 0x22 0xf81 0x24 0xf77 0x25 0xf6a 0x27 0xf57 0x29 0xf40 0x2b 0xf2b 0x2d 0xf1c 0x2e 0xf0f 0x30 0xf03 0x32 0xef9 0x34 0xef0 0x36 0xee8 0x37 0xee1 0x39 0xeda 0x3b 0xed4 0x3d 0xece 0x3e 0xeca 0x40 0xec7 0x42 0xec5 0x44 0xec3 0x46 0xec1 0x47 0xebf 0x49 0xebc 0x4b 0xeb7 0x4d 0xeb0 0x4f 0xea8 0x50 0xea1 0x52 0xe9a 0x54 0xe90 0x56 0xe84 0x57 0xe73 0x59 0xe5d 0x5b 0xe40 0x5d 0xe21 0x5f 0xe03 0x60 0xde8 0x62 0xdc9 0x64 0xd8a>;
			battery_profile_t2_500cycle_1 = <0x00 0x10eb 0x02 0x10d3 0x04 0x10bd 0x05 0x10a7 0x07 0x1092 0x09 0x107d 0x0b 0x1069 0x0c 0x1055 0x0e 0x1042 0x10 0x102f 0x12 0x101d 0x13 0x100a 0x15 0xff8 0x17 0xfe7 0x19 0xfda 0x1b 0xfc5 0x1c 0xfaf 0x1e 0xf9d 0x20 0xf90 0x22 0xf86 0x23 0xf79 0x25 0xf6a 0x27 0xf58 0x29 0xf40 0x2a 0xf2b 0x2c 0xf1c 0x2e 0xf10 0x30 0xf04 0x32 0xefa 0x33 0xef1 0x35 0xee9 0x37 0xee1 0x39 0xeda 0x3a 0xed4 0x3c 0xece 0x3e 0xec9 0x40 0xec5 0x41 0xec2 0x43 0xec0 0x45 0xebf 0x47 0xebc 0x49 0xeb6 0x4a 0xeaf 0x4c 0xea8 0x4e 0xea1 0x50 0xe9c 0x51 0xe96 0x53 0xe8f 0x55 0xe84 0x57 0xe77 0x58 0xe65 0x5a 0xe4a 0x5c 0xe29 0x5e 0xe07 0x60 0xde9 0x61 0xdc5 0x63 0xd81 0x65 0xd15>;
			battery_profile_t3_500cycle_1 = <0x00 0x10e5 0x02 0x10ce 0x04 0x10b8 0x05 0x10a2 0x07 0x108e 0x09 0x1079 0x0b 0x1065 0x0c 0x1052 0x0e 0x103f 0x10 0x102c 0x12 0x101a 0x13 0x1007 0x15 0xff5 0x17 0xfe4 0x19 0xfd2 0x1b 0xfc2 0x1c 0xfb2 0x1e 0xfa2 0x20 0xf93 0x22 0xf84 0x23 0xf76 0x25 0xf68 0x27 0xf56 0x29 0xf3e 0x2b 0xf2a 0x2c 0xf1c 0x2e 0xf10 0x30 0xf05 0x32 0xefa 0x33 0xef1 0x35 0xee8 0x37 0xee0 0x39 0xed9 0x3a 0xed2 0x3c 0xecc 0x3e 0xec7 0x40 0xec2 0x42 0xebe 0x43 0xebb 0x45 0xeb7 0x47 0xeb1 0x49 0xea6 0x4a 0xe9e 0x4c 0xe97 0x4e 0xe90 0x50 0xe8b 0x51 0xe86 0x53 0xe80 0x55 0xe77 0x57 0xe6d 0x59 0xe5f 0x5a 0xe4c 0x5c 0xe30 0x5e 0xe0d 0x60 0xded 0x61 0xdc4 0x63 0xd79 0x65 0xd0e>;
			r_profile_t1_500cycle_1 = <0x21f 0x10ee 0x21f 0x10d1 0x21f 0x10b8 0x21c 0x10a1 0x218 0x108c 0x215 0x1077 0x211 0x1063 0x20f 0x1050 0x20e 0x103d 0x20e 0x102b 0x20d 0x1018 0x20e 0x1005 0x211 0xff5 0x217 0xfe6 0x217 0xfd4 0x213 0xfbc 0x212 0xfa5 0x214 0xf92 0x218 0xf82 0x21d 0xf75 0x21f 0xf68 0x21d 0xf59 0x213 0xf45 0x20a 0xf31 0x205 0xf1f 0x205 0xf10 0x206 0xf03 0x207 0xef8 0x209 0xeee 0x20d 0xee5 0x210 0xedd 0x214 0xed6 0x219 0xecf 0x21e 0xeca 0x225 0xec6 0x22b 0xec2 0x235 0xebe 0x23b 0xebb 0x242 0xeb7 0x24b 0xeb3 0x251 0xeae 0x258 0xea8 0x260 0xea1 0x268 0xe98 0x270 0xe8e 0x278 0xe82 0x283 0xe75 0x28a 0xe65 0x293 0xe53 0x299 0xe3d 0x29f 0xe26 0x2a5 0xe0f 0x2b2 0xdfa 0x2c6 0xde7 0x2e8 0xdd3 0x324 0xdb7 0x390 0xd76 0x86e 0xd31>;
			r_profile_t1_5_500cycle_1 = <0x111 0x10f0 0x111 0x10d6 0x111 0x10bf 0x10f 0x10a9 0x10e 0x1094 0x10b 0x107f 0x10b 0x106b 0x10a 0x1058 0x10a 0x1045 0x10a 0x1032 0x10b 0x101f 0x10c 0x100d 0x10d 0xffb 0x112 0xfec 0x118 0xfde 0x114 0xfc8 0x113 0xfb0 0x116 0xf9b 0x11c 0xf8c 0x123 0xf81 0x12a 0xf77 0x129 0xf6a 0x126 0xf57 0x11c 0xf40 0x113 0xf2b 0x110 0xf1c 0x110 0xf0f 0x110 0xf03 0x111 0xef9 0x113 0xef0 0x115 0xee8 0x118 0xee1 0x11a 0xeda 0x11d 0xed4 0x121 0xece 0x124 0xeca 0x128 0xec7 0x12e 0xec5 0x133 0xec3 0x138 0xec1 0x13c 0xebf 0x140 0xebc 0x142 0xeb7 0x144 0xeb0 0x148 0xea8 0x14e 0xea1 0x156 0xe9a 0x15f 0xe90 0x168 0xe84 0x172 0xe73 0x17c 0xe5d 0x17d 0xe40 0x17c 0xe21 0x17e 0xe03 0x185 0xde8 0x196 0xdc9 0x1a3 0xd8a>;
			r_profile_t2_500cycle_1 = <0xb2 0x10eb 0xb2 0x10d3 0xb2 0x10bd 0xb2 0x10a7 0xb2 0x1092 0xb2 0x107d 0xb2 0x1069 0xb2 0x1055 0xb2 0x1042 0xb4 0x102f 0xb4 0x101d 0xb5 0x100a 0xb7 0xff8 0xb9 0xfe7 0xc0 0xfda 0xbe 0xfc5 0xbd 0xfaf 0xc0 0xf9d 0xc5 0xf90 0xc9 0xf86 0xcb 0xf79 0xcf 0xf6a 0xcf 0xf58 0xc6 0xf40 0xc1 0xf2b 0xc0 0xf1c 0xc0 0xf10 0xc0 0xf04 0xc1 0xefa 0xc2 0xef1 0xc4 0xee9 0xc5 0xee1 0xc7 0xeda 0xc8 0xed4 0xca 0xece 0xcc 0xec9 0xcf 0xec5 0xd2 0xec2 0xd6 0xec0 0xda 0xebf 0xdc 0xebc 0xdb 0xeb6 0xdc 0xeaf 0xdf 0xea8 0xe1 0xea1 0xe5 0xe9c 0xea 0xe96 0xef 0xe8f 0xf4 0xe84 0xfb 0xe77 0x102 0xe65 0x104 0xe4a 0x101 0xe29 0xfd 0xe07 0xff 0xde9 0x107 0xdc5 0x10d 0xd81 0x11c 0xd15>;
			r_profile_t3_500cycle_1 = <0x84 0x10e5 0x84 0x10ce 0x85 0x10b8 0x86 0x10a2 0x86 0x108e 0x86 0x1079 0x86 0x1065 0x87 0x1052 0x87 0x103f 0x87 0x102c 0x88 0x101a 0x88 0x1007 0x89 0xff5 0x8a 0xfe4 0x8b 0xfd2 0x8c 0xfc2 0x8d 0xfb2 0x8f 0xfa2 0x91 0xf93 0x94 0xf84 0x96 0xf76 0x9a 0xf68 0x9b 0xf56 0x95 0xf3e 0x91 0xf2a 0x91 0xf1c 0x92 0xf10 0x92 0xf05 0x93 0xefa 0x94 0xef1 0x94 0xee8 0x95 0xee0 0x96 0xed9 0x97 0xed2 0x98 0xecc 0x99 0xec7 0x9a 0xec2 0x9b 0xebe 0x9c 0xebb 0x9e 0xeb7 0x9c 0xeb1 0x9b 0xea6 0x9e 0xe9e 0xa1 0xe97 0xa3 0xe90 0xa6 0xe8b 0xa8 0xe86 0xab 0xe80 0xad 0xe77 0xb0 0xe6d 0xb4 0xe5f 0xb7 0xe4c 0xb7 0xe30 0xb8 0xe0d 0xbc 0xded 0xc6 0xdc4 0xc5 0xd79 0xcb 0xd0e>;
			linux,phandle = <0xdf>;
			phandle = <0xdf>;
		};

		BAT_NOTIFY {
			compatible = "mediatek,bat_notify";
		};

		bat_comm {
			compatible = "mediatek,battery";
			v_pre2cc_thres = <0xd48>;
			v_cc2topoff_thres = <0xfd2>;
			recharging_voltage = <0x100e>;
			charging_full_current = <0x96>;
			usb_charger_current = <0xc350>;
			ac_charger_input_current = <0x186a0>;
			ac_charger_current = <0x1d4c0>;
			non_std_ac_charger_input_current = <0x186a0>;
			non_std_ac_charger_current = <0x1d4c0>;
			charging_host_charger_current = <0x186a0>;
			apple_0_5a_charger_current = <0xc350>;
			apple_1_0a_charger_current = <0x186a0>;
			apple_2_1a_charger_current = <0x33450>;
			aicl_enable;
			aicl_charging_current_max = <0x249f0>;
			aicl_step_current = <0x2710>;
			aicl_step_interval = <0x64>;
			aicl_vbus_valid = <0x11f8>;
			aicl_vbus_state_phase = <0x0a>;
			ap15_charger_input_current_max = <0x2bf20>;
			ap15_charger_input_current_min = <0x222e0>;
			ap15_dock_input_current_max = <0x2bf20>;
			ap15_dock_input_current_min = <0x222e0>;
			mtk_temperature_recharge_support = <0x01>;
			max_charge_temperature = <0x3c>;
			max_charge_temperature_minus_x_degree = <0x3c>;
			min_charge_temperature = <0x00>;
			min_charge_temperature_plus_x_degree = <0x06>;
			max_charging_time = <0x11940>;
			bat_low_temp_protect_enable = <0x00>;
			v_charger_enable = <0x00>;
			v_charger_max = <0x1964>;
			v_charger_min = <0x1130>;
			onehundred_percent_tracking_time = <0x0a>;
			npercent_tracking_time = <0x14>;
			sync_to_real_tracking_time = <0x3c>;
			v_0percent_tracking = <0xd48>;
			high_battery_voltage_support = <0x01>;
			toggle_charge_enable = <0x01>;
			charge_current_termination = <0xb4>;
			mtk_jeita_standard_support = <0x01>;
			cust_soc_jeita_sync_time = <0x1e>;
			jeita_recharge_voltage = <0x100e>;
			jeita_temp_above_pos_60_cv_voltage = <0x3e8fa0>;
			jeita_temp_pos_45_to_pos_60_cv_voltage = <0x3e8fa0>;
			jeita_temp_pos_10_to_pos_45_cv_voltage = <0x426030>;
			jeita_temp_pos_0_to_pos_10_cv_voltage = <0x426030>;
			jeita_temp_neg_10_to_pos_0_cv_voltage = <0x426030>;
			jeita_temp_below_neg_10_cv_voltage = <0x426030>;
			jeita_neg_10_to_pos_0_full_current = <0x78>;
			jeita_temp_pos_45_to_pos_60_recharge_voltage = <0xfa0>;
			jeita_temp_pos_10_to_pos_45_recharge_voltage = <0x1004>;
			jeita_temp_pos_0_to_pos_10_recharge_voltage = <0x1004>;
			jeita_temp_neg_10_to_pos_0_recharge_voltage = <0x1004>;
			jeita_temp_pos_45_to_pos_60_cc2topoff_threshold = <0xfd2>;
			jeita_temp_pos_10_to_pos_45_cc2topoff_threshold = <0xfd2>;
			jeita_temp_pos_0_to_pos_10_cc2topoff_threshold = <0xfd2>;
			jeita_temp_neg_10_to_pos_0_cc2topoff_threshold = <0xfd2>;
			linux,phandle = <0xe0>;
			phandle = <0xe0>;
		};

		dumchar {
			compatible = "mediatek,mt8163-dummy_char";
		};

		flashlight@ {
			compatible = "mediatek,camera_flashlight";
			linux,phandle = <0xe1>;
			phandle = <0xe1>;
		};

		ice_debug {
			compatible = "mediatek,mt8163-ice_debug\0mediatek,mt8173-ice_debug";
			clocks = <0x0c 0x2f>;
			clock-names = "ice_dbg";
			linux,phandle = <0xe2>;
			phandle = <0xe2>;
		};

		isp_pipemgr {
			compatible = "mediatek,mt8163-isp_pipemgr";
		};

		isp_sysram {
			compatible = "mediatek,mt8163-isp_sysram";
		};

		mtee {
			compatible = "mediatek,mtee";
			clocks = <0x0c 0x20>;
			clock-names = "GCPU";
		};
	};

	lcm {
		compatible = "mediatek,lcm";
		pinctrl-names = "default";
		lcm_pwr_gpio = <0x10 0x20 0x00>;
		lcm_reset_gpio = <0x10 0x58 0x00>;
		reg-lcm-supply = <0x60>;
		linux,phandle = <0xe3>;
		phandle = <0xe3>;
	};

	memory@00000000 {
		device_type = "memory";
		reg = <0x00 0x40000000 0x00 0x20000000>;
	};

	keypanic {
		compatible = "amzn,keypanic";
		keys_down = "KEY_VOLUMEDOWN\0KEY_VOLUMEUP\0KEY_POWER";
		keys_down_delay = <0x1388>;
		status = "okay";
	};

	cust_gsensor@0 {
		compatible = "mediatek,mc3416";
		i2c_num = <0x02>;
		i2c_addr = <0x4c>;
		direction = <0x06>;
		power_id = <0xffff>;
		power_vol = <0x00>;
		firlen = <0x00>;
		is_batch_supported = <0x00>;
	};

	cust_gsensor@1 {
		compatible = "mediatek,bma253";
		i2c_num = <0x02>;
		i2c_addr = <0x18>;
		direction = <0x06>;
		power_id = <0xffff>;
		power_vol = <0x00>;
		firlen = <0x00>;
		is_batch_supported = <0x00>;
	};

	cust_gyroscope@0 {
		compatible = "mediatek,lsm6ds3gy";
		i2c_num = <0x02>;
		i2c_addr = <0x6a>;
		direction = <0x00>;
		power_id = <0xffff>;
		power_vol = <0x00>;
		firlen = <0x00>;
		is_batch_supported = <0x00>;
	};

	chosen {
		bootargs = "console=ttyS0,921600n1 root=/dev/ram initrd=0x44000200,0x200000";
	};

	firmware {
		linux,phandle = <0xe4>;
		phandle = <0xe4>;

		android {
			compatible = "android,firmware";
			linux,phandle = <0xe5>;
			phandle = <0xe5>;

			fstab {
				compatible = "android,fstab";
				linux,phandle = <0xe6>;
				phandle = <0xe6>;

				vendor {
					compatible = "android,vendor";
					dev = "/dev/block/platform/soc/11230000.mmc/by-name/vendor";
					type = "ext4";
					mnt_flags = "ro";
					fsmgr_flags = "wait,verify";
				};
			};
		};
	};

	mtcpufreq {
		compatible = "mediatek,mt8163-cpufreq";
		reg-ext-vproc-supply = <0x61>;
	};

	hall_sensors {
		compatible = "rohm,hall-ah9250";
		interrupt-parent = <0x10>;
		interrupts = <0x56 0x08>;
		int-gpio = <0x10 0x55 0x00>;
		sensor-name = "hall_sensor_1";
		sensor-num = <0x01>;
	};

	cust_alsps@0 {
		compatible = "mediatek,ltr559";
		i2c_num = <0x02>;
		i2c_addr = <0x23>;
		polling_mode_ps = <0x00>;
		polling_mode_als = <0x01>;
		power_id = <0xffff>;
		power_vol = <0x00>;
		als_level = <0x00 0x101 0x27d 0x403 0x8f9 0x15d4 0x1a4a 0x2c25 0x4fe1 0x64a8 0x7992 0xb1f0 0xe251 0xe251 0xe251>;
		als_value = <0x00 0x84 0x130 0x1f6 0x3ec 0x7d3 0xbbe 0x138e 0x1f44 0x2710 0x2ee0 0x3e80 0x4e20 0x4e20 0x4e20 0x4e20>;
		ps_threshold_high = <0x46>;
		ps_threshold_low = <0x28>;
		is_batch_supported_ps = <0x00>;
		is_batch_supported_als = <0x00>;
	};

	thermal-sensor {
		compatible = "generic-adc-thermal";
		#thermal-sensor-cells = <0x00>;
		io-channels = <0x20 0x00 0x20 0x01 0x20 0x0f>;
		io-channel-names = "sensor-channel";
	};

	virtual_sensor@0 {
		compatible = "amazon,virtual_sensor-thermal";
		dev_id = <0x00>;
		num_trips = <0x09>;
		mode = <0x00>;
		polling_delay = <0xbb8>;
		governor_name = "virtual_sensor";
		num_tbps = <0x03>;
		temp = <0xabe0 0xadd4 0xafc8 0xb1bc 0xbf68 0xcb20 0xcf08 0xd2f0 0xdac0 0xdac0 0xdac0 0xdac0>;
		type = <0x00 0x00 0x00 0x00 0x00 0x00 0x00 0x00 0x03 0x03 0x03 0x03>;
		hyst = <0x00 0x00 0x00 0x00 0x00 0x00 0x00 0xbb8 0x00 0x00 0x00 0x00>;
		num_cdevs = <0x02>;
		cdev_names = "thermal_budget0\0lcd-backlight0";
	};

	virtual_sensor@1 {
		compatible = "amazon,virtual_sensor-thermal";
		dev_id = <0x01>;
		num_trips = <0x09>;
		mode = <0x00>;
		polling_delay = <0xbb8>;
		governor_name = "virtual_sensor";
		num_tbps = <0x03>;
		temp = <0xbf68 0xc15c 0xc350 0xc544 0xcf08 0xdac0 0xdea8 0xe290 0xea60 0xea60 0xea60 0xea60>;
		type = <0x00 0x00 0x00 0x00 0x00 0x00 0x00 0x00 0x03 0x03 0x03 0x03>;
		hyst = <0x00 0x00 0x00 0x00 0x00 0x00 0x00 0xbb8 0x00 0x00 0x00 0x00>;
		num_cdevs = <0x02>;
		cdev_names = "thermal_budget1\0bcct1";
	};

	thermal_wmt@0 {
		compatible = "amazon,mtkswmt_sensor";
		thermal_wmt,offset = <0x64>;
		thermal_wmt,alpha = <0x65>;
		thermal_wmt,weight = <0x00>;
		select_device = <0x00>;
	};

	thermal_wmt@1 {
		compatible = "amazon,mtkswmt_sensor";
		thermal_wmt,offset = <0x64>;
		thermal_wmt,alpha = <0x65>;
		thermal_wmt,weight = <0x00>;
		select_device = <0x01>;
	};

	thermal_battery@0 {
		compatible = "amazon,mtksbattery_sensor";
		thermal_battery,offset = <0xa21c>;
		thermal_battery,offset_invert = <0x00>;
		thermal_battery,alpha = <0x2d1>;
		thermal_battery,weight = <0x2b>;
		select_device = <0x00>;
	};

	thermal_battery@1 {
		compatible = "amazon,mtksbattery_sensor";
		thermal_battery,offset = <0xab7c>;
		thermal_battery,offset_invert = <0x00>;
		thermal_battery,alpha = <0x2d0>;
		thermal_battery,weight = <0x10>;
		select_device = <0x01>;
	};

	thermal_gpu@0 {
		compatible = "amazon,mtksgpu_sensor";
		thermal_gpu,offset = <0x64>;
		thermal_gpu,alpha = <0x68>;
		thermal_gpu,weight = <0x00>;
		select_device = <0x00>;
	};

	thermal_gpu@1 {
		compatible = "amazon,mtksgpu_sensor";
		thermal_gpu,offset = <0x64>;
		thermal_gpu,alpha = <0x68>;
		thermal_gpu,weight = <0x00>;
		select_device = <0x01>;
	};

	thermal_pmic@0 {
		compatible = "amazon,mtkspmic_sensor";
		thermal_pmic,offset = <0x10298>;
		thermal_pmic,alpha = <0x1a0>;
		thermal_pmic,weight = <0x12>;
		thermal_pmic,weight_invert = <0x01>;
		select_device = <0x00>;
	};

	thermal_pmic@1 {
		compatible = "amazon,mtkspmic_sensor";
		thermal_pmic,offset = <0xf99c>;
		thermal_pmic,alpha = <0x1a1>;
		thermal_pmic,weight = <0x00>;
		thermal_pmic,weight_invert = <0x00>;
		select_device = <0x01>;
	};

	thermal_cpu@0 {
		compatible = "amazon,mtkscpu_sensor";
		thermal_cpu,offset = <0x64>;
		thermal_cpu,alpha = <0x67>;
		thermal_cpu,weight = <0x00>;
		select_device = <0x00>;
	};

	thermal_cpu@1 {
		compatible = "amazon,mtkscpu_sensor";
		thermal_cpu,offset = <0x64>;
		thermal_cpu,alpha = <0x67>;
		thermal_cpu,weight = <0x00>;
		select_device = <0x01>;
	};

	thermistor@00 {
		compatible = "amazon,virtual_sensor_thermistor";
		thermal_thermistor,offset = <0xc0f8>;
		thermal_thermistor,offset_invert = <0x00>;
		thermal_thermistor,alpha = <0x01>;
		thermal_thermistor,weight = <0x3d>;
		thermal_thermistor,weight_invert = <0x00>;
		aux_channel_num = <0x00>;
		select_device = <0x00>;
	};

	thermistor@01 {
		compatible = "amazon,virtual_sensor_thermistor";
		thermal_thermistor,offset = <0xd804>;
		thermal_thermistor,offset_invert = <0x00>;
		thermal_thermistor,alpha = <0x01>;
		thermal_thermistor,weight = <0x00>;
		thermal_thermistor,weight_invert = <0x00>;
		aux_channel_num = <0x00>;
		select_device = <0x01>;
	};

	thermistor@10 {
		compatible = "amazon,virtual_sensor_thermistor";
		thermal_thermistor,offset = <0xd994>;
		thermal_thermistor,offset_invert = <0x00>;
		thermal_thermistor,alpha = <0x12e>;
		thermal_thermistor,weight = <0x00>;
		thermal_thermistor,weight_invert = <0x00>;
		aux_channel_num = <0x01>;
		select_device = <0x00>;
	};

	thermistor@11 {
		compatible = "amazon,virtual_sensor_thermistor";
		thermal_thermistor,offset = <0xd994>;
		thermal_thermistor,offset_invert = <0x00>;
		thermal_thermistor,alpha = <0x12e>;
		thermal_thermistor,weight = <0x00>;
		thermal_thermistor,weight_invert = <0x00>;
		aux_channel_num = <0x01>;
		select_device = <0x01>;
	};

	thermistor@20 {
		compatible = "amazon,virtual_sensor_thermistor";
		thermal_thermistor,offset = <0x2486>;
		thermal_thermistor,offset_invert = <0x01>;
		thermal_thermistor,alpha = <0xb2>;
		thermal_thermistor,weight = <0x2df>;
		thermal_thermistor,weight_invert = <0x00>;
		aux_channel_num = <0x02>;
		select_device = <0x00>;
	};

	thermistor@21 {
		compatible = "amazon,virtual_sensor_thermistor";
		thermal_thermistor,offset = <0x1fb8>;
		thermal_thermistor,offset_invert = <0x01>;
		thermal_thermistor,alpha = <0xec>;
		thermal_thermistor,weight = <0x338>;
		thermal_thermistor,weight_invert = <0x00>;
		aux_channel_num = <0x02>;
		select_device = <0x01>;
	};

	led@6 {
		compatible = "mediatek,lcd-backlight";
		led_mode = <0x05>;
		data;
		pwm_config = <0x00 0x00 0x00 0x00 0x00>;
		gpios = <0x10 0x3b 0x00>;
		brightness_normalize_param;
	};

	lcm@0 {
		compatible = "lcm,lcm_dts_otm7290b_mustang";
		pinctrl-names = "default";
		lcm_pwr_gpio = <0x10 0x20 0x00>;
		lcm_reset_gpio = <0x10 0x58 0x00>;
		reg-lcm-supply = <0x60>;
		status = "okay";
		linux,phandle = <0xe7>;
		phandle = <0xe7>;
	};

	keysilent-ota {
		compatible = "amzn,silent-ota";
		keys_down = "KEY_POWER";
		keys_down_delay = <0x00>;
		status = "okay";
	};

	integrity-module {
		compatible = "amzn,integrity-module";
		status = "okay";
	};

	__symbols__ {
		cpu0 = "/cpus/cpu@0";
		cpu1 = "/cpus/cpu@1";
		cpu2 = "/cpus/cpu@2";
		cpu3 = "/cpus/cpu@3";
		L2_0 = "/cpus/l2-cache0";
		CPU_SLEEP_0_0 = "/cpus/idle-states/cpu-sleep-0-0";
		CLUSTER_SLEEP_0 = "/cpus/idle-states/cluster-sleep-0";
		MT8163_CPU_COST_0 = "/cpus/energy-costs/mt8163-core-cost0";
		MT8163_CLUSTER_COST_0 = "/cpus/energy-costs/mt8163-cluster-cost0";
		reserved_memory = "/reserved-memory";
		atf_reserved_memory = "/reserved-memory/atf-reserved-memory";
		mdump_reserved_memory = "/reserved-memory/mdump-reserved-memory";
		secure_carveout = "/reserved-memory/secure-carveout";
		clk_null = "/clocks/clk_null";
		clk26m = "/clocks/clk26m";
		clk32k = "/clocks/clk32k";
		chipid = "/soc/chipid@08000000";
		topckgen = "/soc/topckgen@10000000";
		infracfg = "/soc/infracfg@10001000";
		syscfg_pctl_a = "/soc/syscfg_pctl_a@10005000";
		toprgu = "/soc/toprgu@10007000";
		timer = "/soc/apxgpt@10008000";
		pio = "/soc/pinctrl@10005000";
		spi_pins_a = "/soc/pinctrl@10005000/spi1";
		spi_pads = "/soc/pinctrl@10005000/spi1/pins_spi";
		uart0_pin = "/soc/pinctrl@10005000/uart0_pin_default";
		state_default = "/soc/pinctrl@10005000/pinconf_default";
		accdet_pins_default = "/soc/pinctrl@10005000/eint4default";
		accdet_pins_eint_as_int = "/soc/pinctrl@10005000/eint4";
		bq24297_int_pin = "/soc/pinctrl@10005000/bq24297_int_pin";
		bq24297_chg_en_pin = "/soc/pinctrl@10005000/bq24297_chg_en_pin";
		alsps_intpin_cfg = "/soc/pinctrl@10005000/alspspincfg";
		alsps_intpin_default = "/soc/pinctrl@10005000/alspsdefaultcfg";
		aud_pins_default = "/soc/pinctrl@10005000/audiodefault";
		rt551x_pins_eint_as_int = "/soc/pinctrl@10005000/rt551x_irq_init";
		aud_pins_pmicclk_mode0 = "/soc/pinctrl@10005000/pmicclkmode0";
		aud_pins_pmicclk_mode1 = "/soc/pinctrl@10005000/pmicclkmode1";
		camera_pins_default = "/soc/pinctrl@10005000/camdefault";
		camera_pins_cam0_rst0 = "/soc/pinctrl@10005000/cam0@0";
		camera_pins_cam0_rst1 = "/soc/pinctrl@10005000/cam0@1";
		camera_pins_cam0_pnd0 = "/soc/pinctrl@10005000/cam0@2";
		camera_pins_cam0_pnd1 = "/soc/pinctrl@10005000/cam0@3";
		camera_pins_cam1_rst0 = "/soc/pinctrl@10005000/cam1@0";
		camera_pins_cam1_rst1 = "/soc/pinctrl@10005000/cam1@1";
		camera_pins_cam1_pnd0 = "/soc/pinctrl@10005000/cam1@2";
		camera_pins_cam1_pnd1 = "/soc/pinctrl@10005000/cam1@3";
		camera_pins_cam0_rdn0 = "/soc/pinctrl@10005000/cam_pin_rdn0";
		camera_pins_cam0_rdp0 = "/soc/pinctrl@10005000/cam_pin_rdp0";
		camera_pins_cam0_rcn = "/soc/pinctrl@10005000/cam_pin_rcn";
		camera_pins_cam0_rcp = "/soc/pinctrl@10005000/cam_pin_rcp";
		camera_pins_cam1_rcn_a = "/soc/pinctrl@10005000/cam_pin_rcn_a";
		camera_pins_cam1_rcp_a = "/soc/pinctrl@10005000/cam_pin_rcp_a";
		camera_pins_cam1_rdn0_a = "/soc/pinctrl@10005000/cam_pin_rdn0_a";
		camera_pins_cam1_rdp0_a = "/soc/pinctrl@10005000/cam_pin_rdp0_a";
		camera_pins_cam_mclk = "/soc/pinctrl@10005000/cam_pin_mclk";
		lcm_default = "/soc/pinctrl@10005000/default";
		consys_pins_default = "/soc/pinctrl@10005000/default";
		CTP_pins_default = "/soc/pinctrl@10005000/eint0default";
		CTP_pins_eint_as_int = "/soc/pinctrl@10005000/eint@0";
		CTP_pins_eint_output0 = "/soc/pinctrl@10005000/eintoutput0";
		CTP_pins_eint_output1 = "/soc/pinctrl@10005000/eintoutput1";
		CTP_pins_rst_output0 = "/soc/pinctrl@10005000/rstoutput0";
		CTP_pins_rst_output1 = "/soc/pinctrl@10005000/rstoutput1";
		gpio38_mode0_iddig = "/soc/pinctrl@10005000/iddig_irq_init";
		gpio38_mode0_iddig_low = "/soc/pinctrl@10005000/iddig_irq_low";
		gpio38_mode0_iddig_high = "/soc/pinctrl@10005000/iddig_irq_high";
		gpslna_pins_init = "/soc/pinctrl@10005000/gpslna@0";
		gpslna_pins_oh = "/soc/pinctrl@10005000/gpslna@1";
		gpslna_pins_ol = "/soc/pinctrl@10005000/gpslna@2";
		wifi_reset_init = "/soc/pinctrl@10005000/wifireset@0";
		i2c0_pins_a = "/soc/pinctrl@10005000/i2c0@0";
		i2c1_pins_a = "/soc/pinctrl@10005000/i2c1@0";
		i2c2_pins_a = "/soc/pinctrl@10005000/i2c2@0";
		lcm_pwr_high = "/soc/pinctrl@10005000/lcm_gpio@49_high";
		lcm_pwr_low = "/soc/pinctrl@10005000/lcm_gpio@49_low";
		lcm_rst_high = "/soc/pinctrl@10005000/lcm_gpio@48_high";
		lcm_rst_low = "/soc/pinctrl@10005000/lcm_gpio@48_low";
		lcm_pwr_n_high = "/soc/pinctrl@10005000/lcm_gpio@50_high";
		lcm_pwr_n_low = "/soc/pinctrl@10005000/lcm_gpio@50_low";
		mmc0_pins_default = "/soc/pinctrl@10005000/mmc0default";
		mmc0_pins_uhs = "/soc/pinctrl@10005000/mmc0@0";
		mmc1_pins_default = "/soc/pinctrl@10005000/mmc1default";
		mmc1_pins_uhs = "/soc/pinctrl@10005000/mmc1@0";
		dramco = "/soc/dramco@10004000";
		scpsys = "/soc/scpsys@10006000";
		apmixedsys = "/soc/apmixedsys@1000c000";
		pwrap = "/soc/pwrap@0x1000d000";
		pmic = "/soc/pwrap@0x1000d000/mt6323";
		pmicmt6323 = "/soc/pwrap@0x1000d000/mt6323/pmicmt6323";
		mt6323_vproc_reg = "/soc/pwrap@0x1000d000/mt6323/regulators/buck_vproc";
		mt6323_vsys_reg = "/soc/pwrap@0x1000d000/mt6323/regulators/buck_vsys";
		mt6323_vpa_reg = "/soc/pwrap@0x1000d000/mt6323/regulators/buck_vpa";
		mt6323_vtcxo_reg = "/soc/pwrap@0x1000d000/mt6323/regulators/ldo_vtcxo";
		mt6323_vcn28_reg = "/soc/pwrap@0x1000d000/mt6323/regulators/ldo_vcn28";
		mt6323_vcn33_bt_reg = "/soc/pwrap@0x1000d000/mt6323/regulators/ldo_vcn33_bt";
		mt6323_vcn33_wifi_reg = "/soc/pwrap@0x1000d000/mt6323/regulators/ldo_vcn33_wifi";
		mt6323_va_reg = "/soc/pwrap@0x1000d000/mt6323/regulators/ldo_va";
		mt6323_vcama_reg = "/soc/pwrap@0x1000d000/mt6323/regulators/ldo_vcama";
		mt6323_vio28_reg = "/soc/pwrap@0x1000d000/mt6323/regulators/ldo_vio28";
		mt6323_vusb_reg = "/soc/pwrap@0x1000d000/mt6323/regulators/ldo_vusb";
		mt6323_vmc_reg = "/soc/pwrap@0x1000d000/mt6323/regulators/ldo_vmc";
		mt6323_vmch_reg = "/soc/pwrap@0x1000d000/mt6323/regulators/ldo_vmch";
		mt6323_vemc3v3_reg = "/soc/pwrap@0x1000d000/mt6323/regulators/ldo_vemc3v3";
		mt6323_vgp1_reg = "/soc/pwrap@0x1000d000/mt6323/regulators/ldo_vgp1";
		mt6323_vgp2_reg = "/soc/pwrap@0x1000d000/mt6323/regulators/ldo_vgp2";
		mt6323_vgp3_reg = "/soc/pwrap@0x1000d000/mt6323/regulators/ldo_vgp3";
		mt6323_vcn18_reg = "/soc/pwrap@0x1000d000/mt6323/regulators/ldo_vcn18";
		mt6323_vsim1_reg = "/soc/pwrap@0x1000d000/mt6323/regulators/ldo_vsim1";
		mt6323_vsim2_reg = "/soc/pwrap@0x1000d000/mt6323/regulators/ldo_vsim2";
		mt6323_vrtc_reg = "/soc/pwrap@0x1000d000/mt6323/regulators/ldo_vrtc";
		mt6323_vcamaf_reg = "/soc/pwrap@0x1000d000/mt6323/regulators/ldo_vcamaf";
		mt6323_vibr_reg = "/soc/pwrap@0x1000d000/mt6323/regulators/ldo_vibr";
		mt6323_vrf18_reg = "/soc/pwrap@0x1000d000/mt6323/regulators/ldo_vrf18";
		mt6323_vm_reg = "/soc/pwrap@0x1000d000/mt6323/regulators/ldo_vm";
		mt6323_vio18_reg = "/soc/pwrap@0x1000d000/mt6323/regulators/ldo_vio18";
		mt6323_vcamd_reg = "/soc/pwrap@0x1000d000/mt6323/regulators/ldo_vcamd";
		mt6323_vcamio_reg = "/soc/pwrap@0x1000d000/mt6323/regulators/ldo_vcamio";
		ddrphy = "/soc/ddrphy@1000f000";
		keypad = "/soc/keypad@10010000";
		md32 = "/soc/md32@10020000";
		mcucfg = "/soc/mcucfg@10200000";
		cpuxgpt = "/soc/cpuxgpt@10200000";
		lastpc = "/soc/lastpc@10200000";
		sysirq = "/soc/intpol-controller@10200620";
		emi = "/soc/emi@10203000";
		sys_cirq = "/soc/sys_cirq@10204000";
		systracker = "/soc/systracker@10208000";
		dramc_nao = "/soc/dramc_nao@1020e000";
		gcpu = "/soc/gcpu@10210000";
		gce = "/soc/gce@10212000";
		gic = "/soc/interrupt-controller@10221000";
		btif_tx = "/soc/btif_tx@11000700";
		btif_rx = "/soc/btif_rx@11000780";
		apdma = "/soc/dma-controller@0x11000300";
		auxadc = "/soc/auxadc@11001000";
		uart0 = "/soc/serial@11002000";
		uart1 = "/soc/serial@11003000";
		uart2 = "/soc/serial@11004000";
		uart3 = "/soc/serial@11005000";
		pwm = "/soc/pwm@11006000";
		i2c0 = "/soc/i2c@11007000";
		rt551x = "/soc/i2c@11007000/audio-codec@57";
		i2c1 = "/soc/i2c@11008000";
		vproc = "/soc/i2c@11008000/sym827@60";
		i2c2 = "/soc/i2c@11009000";
		spi = "/soc/spi@1100a000";
		rt551x_spi = "/soc/spi@1100a000/audio-codec@0";
		thermal = "/soc/thermal@1100b000";
		tboard_thermistor = "/soc/thermal-sensor";
		ptp_od = "/soc/ptp_od@1100b000";
		btif = "/soc/btif@1100c000";
		nfi = "/soc/nfi@1100d000";
		nfiecc = "/soc/nfiecc@1100e000";
		usb0 = "/soc/usb@11200000";
		audiosys = "/soc/audiosys@11220000";
		audgpio = "/soc/mt_soc_dl1_pcm@11220000";
		mfg = "/soc/mfg@13000000";
		mali = "/soc/gpu@13040000";
		mmc0 = "/soc/mmc@11230000";
		mmc1 = "/soc/mmc@11240000";
		mmc2 = "/soc/mmc@11250000";
		usb1 = "/soc/usb@11270000";
		mmsys = "/soc/mmsys@14000000";
		mdp_rdma = "/soc/mdp_rdma@14001000";
		mdp_rsz0 = "/soc/mdp_rsz0@14002000";
		mdp_rsz1 = "/soc/mdp_rsz1@14003000";
		mdp_wdma = "/soc/mdp_wdma@14004000";
		mdp_wrot = "/soc/mdp_wrot@14005000";
		mdp_tdshp = "/soc/mdp_tdshp@14006000";
		dispsys = "/soc/mt8163-dispsys";
		disp_ovl0 = "/soc/disp_ovl0@14007000";
		disp_ovl1 = "/soc/disp_ovl1@14008000";
		disp_rdma0 = "/soc/disp_rdma0@14009000";
		disp_rdma1 = "/soc/disp_rdma1@1400a000";
		disp_wdma0 = "/soc/disp_wdma0@1400b000";
		disp_color = "/soc/disp_color@1400c000";
		disp_ccorr = "/soc/disp_ccorr@1400d000";
		disp_aal = "/soc/disp_aal@1400e000";
		disp_gamma = "/soc/disp_gamma@1400f000";
		disp_dither = "/soc/disp_dither@14010000";
		disp_ufoe = "/soc/disp_ufoe@14011000";
		disp_dsi0 = "/soc/disp_dsi0@14012000";
		disp_dpi0 = "/soc/disp_dpi0@14013000";
		disp_dpi1 = "/soc/disp_dpi1@1401c000";
		hdmi0 = "/soc/hdmi@1401d000";
		disp_pwm0 = "/soc/disp_pwm0@14014000";
		mm_mutex = "/soc/mm_mutex@14015000";
		disp_wdma1 = "/soc/disp_wdma1@14018000";
		disp_config2 = "/soc/disp_config2@10206000";
		disp_config3 = "/soc/disp_config3@10000000";
		disp_mipi = "/soc/disp_mipi@10215000";
		disp_io_driving = "/soc/disp_io_driving@10005000";
		disp_tvdpll_cfg6 = "/soc/disp_tvdpll_cfg6@100000a0";
		disp_tvdpll_con0 = "/soc/disp_tvdpll_con0@1000c270";
		disp_tvdpll_con1 = "/soc/disp_tvdpll_con1@1000c274";
		disp_lvds_ana = "/soc/disp_lvds_ana@10215800";
		larb0 = "/soc/larb@14016000";
		smi_common = "/soc/smi@14017000";
		met_smi = "/soc/met_smi@14017000";
		disp_lvds_tx = "/soc/disp_lvds_tx@1401b200";
		imgsys = "/soc/imgsys@15000000";
		isp_display = "/soc/isp_display";
		ispsys = "/soc/ispsys@15000000";
		larb2 = "/soc/larb@15001000";
		kd_camera_hw1 = "/soc/camera1@15008000";
		kd_camera_hw2 = "/soc/camera2@15008000";
		vdecsys = "/soc/vdecsys@16000000";
		larb1 = "/soc/larb@16010000";
		vencsys = "/soc/vencsys@17000000";
		larb3 = "/soc/larb@17001000";
		consys = "/soc/consys@18070000";
		accdet = "/soc/accdet@";
		touch = "/soc/touch@";
		alsps = "/soc/als_ps@0";
		gyro = "/soc/gyroscope@0";
		led0 = "/soc/led@0";
		led1 = "/soc/led@1";
		led2 = "/soc/led@2";
		led3 = "/soc/led@3";
		led4 = "/soc/led@4";
		led5 = "/soc/led@5";
		led6 = "/soc/led@6";
		mtkfb = "/soc/mtkfb@0";
		bat_meter = "/soc/bat_meter";
		bat_comm = "/soc/bat_comm";
		flashlight = "/soc/flashlight@";
		ice = "/soc/ice_debug";
		lcm = "/lcm";
		firmware = "/firmware";
		android = "/firmware/android";
		fstab = "/firmware/android/fstab";
		lcm0 = "/lcm@0";
	};
};
